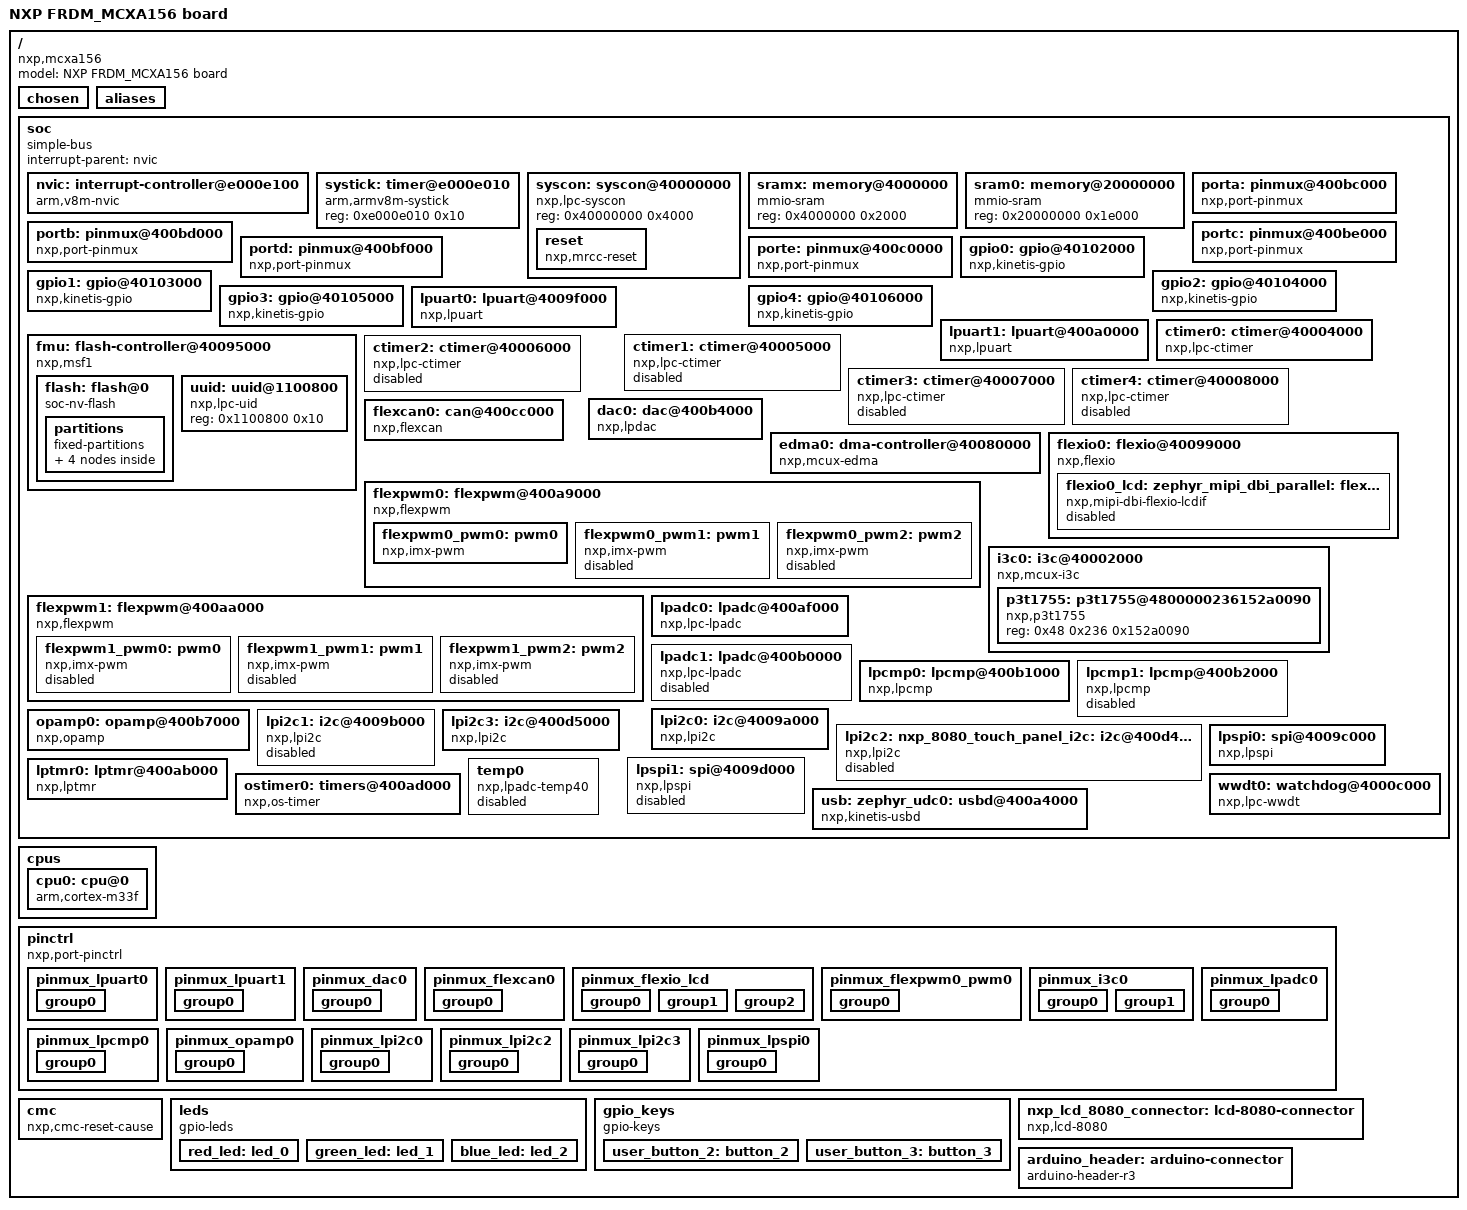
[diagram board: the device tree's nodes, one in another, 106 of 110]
/dts-v1/;

/* node '/' defined in zephyr/dts/common/skeleton.dtsi:9 */
/ {
	#address-cells = < 0x1 >;         /* in zephyr/dts/common/skeleton.dtsi:10 */
	#size-cells = < 0x1 >;            /* in zephyr/dts/common/skeleton.dtsi:11 */
	model = "NXP FRDM_MCXA156 board"; /* in zephyr/boards/nxp/frdm_mcxa156/frdm_mcxa156.dts:16 */
	compatible = "nxp,mcxa156",
	             "nxp,mcx";           /* in zephyr/boards/nxp/frdm_mcxa156/frdm_mcxa156.dts:17 */

	/* node '/chosen' defined in zephyr/dts/common/skeleton.dtsi:13 */
	chosen {
		zephyr,sram = &sram0;                     /* in zephyr/boards/nxp/frdm_mcxa156/frdm_mcxa156.dts:33 */
		zephyr,flash = &flash;                    /* in zephyr/boards/nxp/frdm_mcxa156/frdm_mcxa156.dts:34 */
		zephyr,flash-controller = &fmu;           /* in zephyr/boards/nxp/frdm_mcxa156/frdm_mcxa156.dts:35 */
		zephyr,code-partition = &slot0_partition; /* in zephyr/boards/nxp/frdm_mcxa156/frdm_mcxa156.dts:36 */
		zephyr,console = &lpuart0;                /* in zephyr/boards/nxp/frdm_mcxa156/frdm_mcxa156.dts:37 */
		zephyr,shell-uart = &lpuart0;             /* in zephyr/boards/nxp/frdm_mcxa156/frdm_mcxa156.dts:38 */
		zephyr,uart-mcumgr = &lpuart0;            /* in zephyr/boards/nxp/frdm_mcxa156/frdm_mcxa156.dts:39 */
		zephyr,canbus = &flexcan0;                /* in zephyr/boards/nxp/frdm_mcxa156/frdm_mcxa156.dts:40 */
	};

	/* node '/aliases' defined in zephyr/dts/common/skeleton.dtsi:15 */
	aliases {
		led0 = &red_led;                  /* in zephyr/boards/nxp/frdm_mcxa156/frdm_mcxa156.dts:20 */
		led1 = &green_led;                /* in zephyr/boards/nxp/frdm_mcxa156/frdm_mcxa156.dts:21 */
		led2 = &blue_led;                 /* in zephyr/boards/nxp/frdm_mcxa156/frdm_mcxa156.dts:22 */
		sw0 = &user_button_2;             /* in zephyr/boards/nxp/frdm_mcxa156/frdm_mcxa156.dts:23 */
		sw1 = &user_button_3;             /* in zephyr/boards/nxp/frdm_mcxa156/frdm_mcxa156.dts:24 */
		pwm-0 = &flexpwm0_pwm0;           /* in zephyr/boards/nxp/frdm_mcxa156/frdm_mcxa156.dts:25 */
		mcuboot-button0 = &user_button_2; /* in zephyr/boards/nxp/frdm_mcxa156/frdm_mcxa156.dts:26 */
		watchdog0 = &wwdt0;               /* in zephyr/boards/nxp/frdm_mcxa156/frdm_mcxa156.dts:27 */
		ambient-temp0 = &p3t1755;         /* in zephyr/boards/nxp/frdm_mcxa156/frdm_mcxa156.dts:28 */
		die-temp0 = &temp0;               /* in zephyr/boards/nxp/frdm_mcxa156/frdm_mcxa156.dts:29 */
	};

	/* node '/soc' defined in zephyr/dts/arm/armv8-m.dtsi:6 */
	soc {
		#address-cells = < 0x1 >;     /* in zephyr/dts/arm/armv8-m.dtsi:7 */
		#size-cells = < 0x1 >;        /* in zephyr/dts/arm/armv8-m.dtsi:8 */
		compatible = "simple-bus";    /* in zephyr/dts/arm/armv8-m.dtsi:9 */
		interrupt-parent = < &nvic >; /* in zephyr/dts/arm/armv8-m.dtsi:10 */
		ranges;                       /* in zephyr/dts/arm/armv8-m.dtsi:11 */

		/* node '/soc/interrupt-controller@e000e100' defined in zephyr/dts/arm/armv8-m.dtsi:13 */
		nvic: interrupt-controller@e000e100 {
			#address-cells = < 0x1 >;            /* in zephyr/dts/arm/armv8-m.dtsi:14 */
			compatible = "arm,v8m-nvic";         /* in zephyr/dts/arm/armv8-m.dtsi:15 */
			reg = < 0xe000e100 0xc00 >;          /* in zephyr/dts/arm/armv8-m.dtsi:16 */
			interrupt-controller;                /* in zephyr/dts/arm/armv8-m.dtsi:17 */
			#interrupt-cells = < 0x2 >;          /* in zephyr/dts/arm/armv8-m.dtsi:18 */
			arm,num-irq-priority-bits = < 0x3 >; /* in zephyr/dts/arm/nxp/nxp_mcxa156.dtsi:547 */
			phandle = < 0x1 >;                   /* in zephyr/dts/arm/armv8-m.dtsi:10 */
		};

		/* node '/soc/timer@e000e010' defined in zephyr/dts/arm/armv8-m.dtsi:21 */
		systick: timer@e000e010 {
			compatible = "arm,armv8m-systick"; /* in zephyr/dts/arm/armv8-m.dtsi:22 */
			reg = < 0xe000e010 0x10 >;         /* in zephyr/dts/arm/armv8-m.dtsi:23 */
		};

		/* node '/soc/syscon@40000000' defined in zephyr/dts/arm/nxp/nxp_mcxa156.dtsi:38 */
		syscon: syscon@40000000 {
			compatible = "nxp,lpc-syscon"; /* in zephyr/dts/arm/nxp/nxp_mcxa156.dtsi:39 */
			reg = < 0x40000000 0x4000 >;   /* in zephyr/dts/arm/nxp/nxp_mcxa156.dtsi:40 */
			#clock-cells = < 0x1 >;        /* in zephyr/dts/arm/nxp/nxp_mcxa156.dtsi:41 */
			phandle = < 0x2 >;             /* in zephyr/dts/arm/nxp/nxp_mcxa156.dtsi:62 */

			/* node '/soc/syscon@40000000/reset' defined in zephyr/dts/arm/nxp/nxp_mcxa156.dtsi:43 */
			reset: reset {
				compatible = "nxp,mrcc-reset"; /* in zephyr/dts/arm/nxp/nxp_mcxa156.dtsi:44 */
				#reset-cells = < 0x1 >;        /* in zephyr/dts/arm/nxp/nxp_mcxa156.dtsi:45 */
			};
		};

		/* node '/soc/memory@4000000' defined in zephyr/dts/arm/nxp/nxp_mcxa156.dtsi:49 */
		sramx: memory@4000000 {
			compatible = "mmio-sram";   /* in zephyr/dts/arm/nxp/nxp_mcxa156.dtsi:50 */
			reg = < 0x4000000 0x2000 >; /* in zephyr/dts/arm/nxp/nxp_mcxa156.dtsi:51 */
		};

		/* node '/soc/memory@20000000' defined in zephyr/dts/arm/nxp/nxp_mcxa156.dtsi:54 */
		sram0: memory@20000000 {
			compatible = "mmio-sram";     /* in zephyr/dts/arm/nxp/nxp_mcxa156.dtsi:55 */
			reg = < 0x20000000 0x1e000 >; /* in zephyr/dts/arm/nxp/nxp_mcxa156.dtsi:56 */
		};

		/* node '/soc/pinmux@400bc000' defined in zephyr/dts/arm/nxp/nxp_mcxa156.dtsi:59 */
		porta: pinmux@400bc000 {
			compatible = "nxp,port-pinmux"; /* in zephyr/dts/arm/nxp/nxp_mcxa156.dtsi:60 */
			reg = < 0x400bc000 0x1000 >;    /* in zephyr/dts/arm/nxp/nxp_mcxa156.dtsi:61 */
			clocks = < &syscon 0xc00 >;     /* in zephyr/dts/arm/nxp/nxp_mcxa156.dtsi:62 */
			phandle = < 0x3 >;              /* in zephyr/dts/arm/nxp/nxp_mcxa156.dtsi:95 */
		};

		/* node '/soc/pinmux@400bd000' defined in zephyr/dts/arm/nxp/nxp_mcxa156.dtsi:65 */
		portb: pinmux@400bd000 {
			compatible = "nxp,port-pinmux"; /* in zephyr/dts/arm/nxp/nxp_mcxa156.dtsi:66 */
			reg = < 0x400bd000 0x1000 >;    /* in zephyr/dts/arm/nxp/nxp_mcxa156.dtsi:67 */
			clocks = < &syscon 0xc01 >;     /* in zephyr/dts/arm/nxp/nxp_mcxa156.dtsi:68 */
			phandle = < 0x4 >;              /* in zephyr/dts/arm/nxp/nxp_mcxa156.dtsi:105 */
		};

		/* node '/soc/pinmux@400be000' defined in zephyr/dts/arm/nxp/nxp_mcxa156.dtsi:71 */
		portc: pinmux@400be000 {
			compatible = "nxp,port-pinmux"; /* in zephyr/dts/arm/nxp/nxp_mcxa156.dtsi:72 */
			reg = < 0x400be000 0x1000 >;    /* in zephyr/dts/arm/nxp/nxp_mcxa156.dtsi:73 */
			clocks = < &syscon 0xc02 >;     /* in zephyr/dts/arm/nxp/nxp_mcxa156.dtsi:74 */
			phandle = < 0x5 >;              /* in zephyr/dts/arm/nxp/nxp_mcxa156.dtsi:115 */
		};

		/* node '/soc/pinmux@400bf000' defined in zephyr/dts/arm/nxp/nxp_mcxa156.dtsi:77 */
		portd: pinmux@400bf000 {
			compatible = "nxp,port-pinmux"; /* in zephyr/dts/arm/nxp/nxp_mcxa156.dtsi:78 */
			reg = < 0x400bf000 0x1000 >;    /* in zephyr/dts/arm/nxp/nxp_mcxa156.dtsi:79 */
			clocks = < &syscon 0xc03 >;     /* in zephyr/dts/arm/nxp/nxp_mcxa156.dtsi:80 */
			phandle = < 0x6 >;              /* in zephyr/dts/arm/nxp/nxp_mcxa156.dtsi:125 */
		};

		/* node '/soc/pinmux@400c0000' defined in zephyr/dts/arm/nxp/nxp_mcxa156.dtsi:83 */
		porte: pinmux@400c0000 {
			compatible = "nxp,port-pinmux"; /* in zephyr/dts/arm/nxp/nxp_mcxa156.dtsi:84 */
			reg = < 0x400c0000 0x1000 >;    /* in zephyr/dts/arm/nxp/nxp_mcxa156.dtsi:85 */
			clocks = < &syscon 0xc04 >;     /* in zephyr/dts/arm/nxp/nxp_mcxa156.dtsi:86 */
			phandle = < 0x7 >;              /* in zephyr/dts/arm/nxp/nxp_mcxa156.dtsi:135 */
		};

		/* node '/soc/gpio@40102000' defined in zephyr/dts/arm/nxp/nxp_mcxa156.dtsi:89 */
		gpio0: gpio@40102000 {
			compatible = "nxp,kinetis-gpio"; /* in zephyr/dts/arm/nxp/nxp_mcxa156.dtsi:90 */
			reg = < 0x40102000 0x1000 >;     /* in zephyr/dts/arm/nxp/nxp_mcxa156.dtsi:91 */
			interrupts = < 0x47 0x0 >;       /* in zephyr/dts/arm/nxp/nxp_mcxa156.dtsi:92 */
			gpio-controller;                 /* in zephyr/dts/arm/nxp/nxp_mcxa156.dtsi:93 */
			#gpio-cells = < 0x2 >;           /* in zephyr/dts/arm/nxp/nxp_mcxa156.dtsi:94 */
			nxp,kinetis-port = < &porta >;   /* in zephyr/dts/arm/nxp/nxp_mcxa156.dtsi:95 */
			status = "okay";                 /* in zephyr/boards/nxp/frdm_mcxa156/frdm_mcxa156.dts:126 */
			phandle = < 0x1a >;              /* in zephyr/boards/nxp/frdm_mcxa156/frdm_mcxa156.dts:73 */
		};

		/* node '/soc/gpio@40103000' defined in zephyr/dts/arm/nxp/nxp_mcxa156.dtsi:98 */
		gpio1: gpio@40103000 {
			compatible = "nxp,kinetis-gpio"; /* in zephyr/dts/arm/nxp/nxp_mcxa156.dtsi:99 */
			reg = < 0x40103000 0x1000 >;     /* in zephyr/dts/arm/nxp/nxp_mcxa156.dtsi:101 */
			interrupts = < 0x48 0x0 >;       /* in zephyr/dts/arm/nxp/nxp_mcxa156.dtsi:102 */
			gpio-controller;                 /* in zephyr/dts/arm/nxp/nxp_mcxa156.dtsi:103 */
			#gpio-cells = < 0x2 >;           /* in zephyr/dts/arm/nxp/nxp_mcxa156.dtsi:104 */
			nxp,kinetis-port = < &portb >;   /* in zephyr/dts/arm/nxp/nxp_mcxa156.dtsi:105 */
			status = "okay";                 /* in zephyr/boards/nxp/frdm_mcxa156/frdm_mcxa156.dts:130 */
			phandle = < 0x19 >;              /* in zephyr/boards/nxp/frdm_mcxa156/frdm_mcxa156.dts:67 */
		};

		/* node '/soc/gpio@40104000' defined in zephyr/dts/arm/nxp/nxp_mcxa156.dtsi:108 */
		gpio2: gpio@40104000 {
			compatible = "nxp,kinetis-gpio"; /* in zephyr/dts/arm/nxp/nxp_mcxa156.dtsi:109 */
			reg = < 0x40104000 0x1000 >;     /* in zephyr/dts/arm/nxp/nxp_mcxa156.dtsi:111 */
			interrupts = < 0x49 0x0 >;       /* in zephyr/dts/arm/nxp/nxp_mcxa156.dtsi:112 */
			gpio-controller;                 /* in zephyr/dts/arm/nxp/nxp_mcxa156.dtsi:113 */
			#gpio-cells = < 0x2 >;           /* in zephyr/dts/arm/nxp/nxp_mcxa156.dtsi:114 */
			nxp,kinetis-port = < &portc >;   /* in zephyr/dts/arm/nxp/nxp_mcxa156.dtsi:115 */
			status = "okay";                 /* in zephyr/boards/nxp/frdm_mcxa156/frdm_mcxa156.dts:134 */
			phandle = < 0xe >;               /* in zephyr/boards/nxp/frdm_mcxa156/frdm_mcxa156.dts:198 */
		};

		/* node '/soc/gpio@40105000' defined in zephyr/dts/arm/nxp/nxp_mcxa156.dtsi:118 */
		gpio3: gpio@40105000 {
			compatible = "nxp,kinetis-gpio"; /* in zephyr/dts/arm/nxp/nxp_mcxa156.dtsi:119 */
			reg = < 0x40105000 0x1000 >;     /* in zephyr/dts/arm/nxp/nxp_mcxa156.dtsi:121 */
			interrupts = < 0x4a 0x0 >;       /* in zephyr/dts/arm/nxp/nxp_mcxa156.dtsi:122 */
			gpio-controller;                 /* in zephyr/dts/arm/nxp/nxp_mcxa156.dtsi:123 */
			#gpio-cells = < 0x2 >;           /* in zephyr/dts/arm/nxp/nxp_mcxa156.dtsi:124 */
			nxp,kinetis-port = < &portd >;   /* in zephyr/dts/arm/nxp/nxp_mcxa156.dtsi:125 */
			status = "okay";                 /* in zephyr/boards/nxp/frdm_mcxa156/frdm_mcxa156.dts:138 */
			phandle = < 0xd >;               /* in zephyr/boards/nxp/frdm_mcxa156/frdm_mcxa156.dts:197 */
		};

		/* node '/soc/gpio@40106000' defined in zephyr/dts/arm/nxp/nxp_mcxa156.dtsi:128 */
		gpio4: gpio@40106000 {
			compatible = "nxp,kinetis-gpio"; /* in zephyr/dts/arm/nxp/nxp_mcxa156.dtsi:129 */
			reg = < 0x40106000 0x1000 >;     /* in zephyr/dts/arm/nxp/nxp_mcxa156.dtsi:131 */
			interrupts = < 0x4b 0x0 >;       /* in zephyr/dts/arm/nxp/nxp_mcxa156.dtsi:132 */
			gpio-controller;                 /* in zephyr/dts/arm/nxp/nxp_mcxa156.dtsi:133 */
			#gpio-cells = < 0x2 >;           /* in zephyr/dts/arm/nxp/nxp_mcxa156.dtsi:134 */
			nxp,kinetis-port = < &porte >;   /* in zephyr/dts/arm/nxp/nxp_mcxa156.dtsi:135 */
			status = "okay";                 /* in zephyr/boards/nxp/frdm_mcxa156/frdm_mcxa156.dts:142 */
		};

		/* node '/soc/lpuart@4009f000' defined in zephyr/dts/arm/nxp/nxp_mcxa156.dtsi:138 */
		lpuart0: lpuart@4009f000 {
			compatible = "nxp,lpuart";       /* in zephyr/dts/arm/nxp/nxp_mcxa156.dtsi:139 */
			reg = < 0x4009f000 0x1000 >;     /* in zephyr/dts/arm/nxp/nxp_mcxa156.dtsi:140 */
			interrupts = < 0x1f 0x0 >;       /* in zephyr/dts/arm/nxp/nxp_mcxa156.dtsi:141 */
			clocks = < &syscon 0x1300 >;     /* in zephyr/dts/arm/nxp/nxp_mcxa156.dtsi:142 */
			dmas = < &edma0 0x0 0x15 >,
			       < &edma0 0x1 0x16 >;      /* in zephyr/dts/arm/nxp/nxp_mcxa156.dtsi:144 */
			dma-names = "rx",
			            "tx";                /* in zephyr/dts/arm/nxp/nxp_mcxa156.dtsi:145 */
			status = "okay";                 /* in zephyr/boards/nxp/frdm_mcxa156/frdm_mcxa156.dts:146 */
			current-speed = < 0x1c200 >;     /* in zephyr/boards/nxp/frdm_mcxa156/frdm_mcxa156.dts:147 */
			pinctrl-0 = < &pinmux_lpuart0 >; /* in zephyr/boards/nxp/frdm_mcxa156/frdm_mcxa156.dts:148 */
			pinctrl-names = "default";       /* in zephyr/boards/nxp/frdm_mcxa156/frdm_mcxa156.dts:149 */
		};

		/* node '/soc/lpuart@400a0000' defined in zephyr/dts/arm/nxp/nxp_mcxa156.dtsi:148 */
		lpuart1: lpuart@400a0000 {
			compatible = "nxp,lpuart";       /* in zephyr/dts/arm/nxp/nxp_mcxa156.dtsi:149 */
			reg = < 0x400a0000 0x1000 >;     /* in zephyr/dts/arm/nxp/nxp_mcxa156.dtsi:150 */
			interrupts = < 0x20 0x0 >;       /* in zephyr/dts/arm/nxp/nxp_mcxa156.dtsi:151 */
			clocks = < &syscon 0x1301 >;     /* in zephyr/dts/arm/nxp/nxp_mcxa156.dtsi:152 */
			dmas = < &edma0 0x2 0x17 >,
			       < &edma0 0x3 0x18 >;      /* in zephyr/dts/arm/nxp/nxp_mcxa156.dtsi:154 */
			dma-names = "rx",
			            "tx";                /* in zephyr/dts/arm/nxp/nxp_mcxa156.dtsi:155 */
			status = "okay";                 /* in zephyr/boards/nxp/frdm_mcxa156/frdm_mcxa156.dts:153 */
			current-speed = < 0x1c200 >;     /* in zephyr/boards/nxp/frdm_mcxa156/frdm_mcxa156.dts:154 */
			pinctrl-0 = < &pinmux_lpuart1 >; /* in zephyr/boards/nxp/frdm_mcxa156/frdm_mcxa156.dts:155 */
			pinctrl-names = "default";       /* in zephyr/boards/nxp/frdm_mcxa156/frdm_mcxa156.dts:156 */
		};

		/* node '/soc/flash-controller@40095000' defined in zephyr/dts/arm/nxp/nxp_mcxa156.dtsi:158 */
		fmu: flash-controller@40095000 {
			compatible = "nxp,msf1";     /* in zephyr/dts/arm/nxp/nxp_mcxa156.dtsi:159 */
			reg = < 0x40095000 0x1000 >; /* in zephyr/dts/arm/nxp/nxp_mcxa156.dtsi:160 */
			interrupts = < 0xc 0x0 >;    /* in zephyr/dts/arm/nxp/nxp_mcxa156.dtsi:161 */
			#address-cells = < 0x1 >;    /* in zephyr/dts/arm/nxp/nxp_mcxa156.dtsi:163 */
			#size-cells = < 0x1 >;       /* in zephyr/dts/arm/nxp/nxp_mcxa156.dtsi:164 */

			/* node '/soc/flash-controller@40095000/flash@0' defined in zephyr/dts/arm/nxp/nxp_mcxa156.dtsi:166 */
			flash: flash@0 {
				compatible = "soc-nv-flash";   /* in zephyr/dts/arm/nxp/nxp_mcxa156.dtsi:167 */
				reg = < 0x0 0x100000 >;        /* in zephyr/dts/arm/nxp/nxp_mcxa156.dtsi:168 */
				erase-block-size = < 0x2000 >; /* in zephyr/dts/arm/nxp/nxp_mcxa156.dtsi:169 */
				write-block-size = < 0x10 >;   /* in zephyr/dts/arm/nxp/nxp_mcxa156.dtsi:170 */

				/* node '/soc/flash-controller@40095000/flash@0/partitions' defined in zephyr/boards/nxp/frdm_mcxa156/frdm_mcxa156.dts:283 */
				partitions {
					compatible = "fixed-partitions"; /* in zephyr/boards/nxp/frdm_mcxa156/frdm_mcxa156.dts:284 */
					#address-cells = < 0x1 >;        /* in zephyr/boards/nxp/frdm_mcxa156/frdm_mcxa156.dts:285 */
					#size-cells = < 0x1 >;           /* in zephyr/boards/nxp/frdm_mcxa156/frdm_mcxa156.dts:286 */

					/* node '/soc/flash-controller@40095000/flash@0/partitions/partition@0' defined in zephyr/boards/nxp/frdm_mcxa156/frdm_mcxa156.dts:288 */
					boot_partition: partition@0 {
						label = "mcuboot";     /* in zephyr/boards/nxp/frdm_mcxa156/frdm_mcxa156.dts:289 */
						reg = < 0x0 0x10000 >; /* in zephyr/boards/nxp/frdm_mcxa156/frdm_mcxa156.dts:290 */
						read-only;             /* in zephyr/boards/nxp/frdm_mcxa156/frdm_mcxa156.dts:291 */
					};

					/* node '/soc/flash-controller@40095000/flash@0/partitions/partition@10000' defined in zephyr/boards/nxp/frdm_mcxa156/frdm_mcxa156.dts:294 */
					slot0_partition: partition@10000 {
						label = "image-0";         /* in zephyr/boards/nxp/frdm_mcxa156/frdm_mcxa156.dts:295 */
						reg = < 0x10000 0x6a000 >; /* in zephyr/boards/nxp/frdm_mcxa156/frdm_mcxa156.dts:296 */
					};

					/* node '/soc/flash-controller@40095000/flash@0/partitions/partition@7a000' defined in zephyr/boards/nxp/frdm_mcxa156/frdm_mcxa156.dts:299 */
					slot1_partition: partition@7a000 {
						label = "image-1";         /* in zephyr/boards/nxp/frdm_mcxa156/frdm_mcxa156.dts:300 */
						reg = < 0x7a000 0x6a000 >; /* in zephyr/boards/nxp/frdm_mcxa156/frdm_mcxa156.dts:301 */
					};

					/* node '/soc/flash-controller@40095000/flash@0/partitions/partition@e4000' defined in zephyr/boards/nxp/frdm_mcxa156/frdm_mcxa156.dts:304 */
					storage_partition: partition@e4000 {
						label = "storage";         /* in zephyr/boards/nxp/frdm_mcxa156/frdm_mcxa156.dts:305 */
						reg = < 0xe4000 0x1c000 >; /* in zephyr/boards/nxp/frdm_mcxa156/frdm_mcxa156.dts:306 */
					};
				};
			};

			/* node '/soc/flash-controller@40095000/uuid@1100800' defined in zephyr/dts/arm/nxp/nxp_mcxa156.dtsi:173 */
			uuid: uuid@1100800 {
				compatible = "nxp,lpc-uid"; /* in zephyr/dts/arm/nxp/nxp_mcxa156.dtsi:174 */
				reg = < 0x1100800 0x10 >;   /* in zephyr/dts/arm/nxp/nxp_mcxa156.dtsi:175 */
			};
		};

		/* node '/soc/ctimer@40004000' defined in zephyr/dts/arm/nxp/nxp_mcxa156.dtsi:179 */
		ctimer0: ctimer@40004000 {
			compatible = "nxp,lpc-ctimer"; /* in zephyr/dts/arm/nxp/nxp_mcxa156.dtsi:180 */
			reg = < 0x40004000 0x1000 >;   /* in zephyr/dts/arm/nxp/nxp_mcxa156.dtsi:181 */
			interrupts = < 0x27 0x0 >;     /* in zephyr/dts/arm/nxp/nxp_mcxa156.dtsi:182 */
			clk-source = < 0x1 >;          /* in zephyr/dts/arm/nxp/nxp_mcxa156.dtsi:184 */
			clocks = < &syscon 0x0 >;      /* in zephyr/dts/arm/nxp/nxp_mcxa156.dtsi:185 */
			mode = < 0x0 >;                /* in zephyr/dts/arm/nxp/nxp_mcxa156.dtsi:186 */
			input = < 0x0 >;               /* in zephyr/dts/arm/nxp/nxp_mcxa156.dtsi:187 */
			prescale = < 0x0 >;            /* in zephyr/dts/arm/nxp/nxp_mcxa156.dtsi:188 */
			status = "okay";               /* in zephyr/boards/nxp/frdm_mcxa156/frdm_mcxa156.dts:160 */
		};

		/* node '/soc/ctimer@40005000' defined in zephyr/dts/arm/nxp/nxp_mcxa156.dtsi:191 */
		ctimer1: ctimer@40005000 {
			compatible = "nxp,lpc-ctimer"; /* in zephyr/dts/arm/nxp/nxp_mcxa156.dtsi:192 */
			reg = < 0x40005000 0x1000 >;   /* in zephyr/dts/arm/nxp/nxp_mcxa156.dtsi:193 */
			interrupts = < 0x28 0x0 >;     /* in zephyr/dts/arm/nxp/nxp_mcxa156.dtsi:194 */
			status = "disabled";           /* in zephyr/dts/arm/nxp/nxp_mcxa156.dtsi:195 */
			clk-source = < 0x1 >;          /* in zephyr/dts/arm/nxp/nxp_mcxa156.dtsi:196 */
			clocks = < &syscon 0x1 >;      /* in zephyr/dts/arm/nxp/nxp_mcxa156.dtsi:197 */
			mode = < 0x0 >;                /* in zephyr/dts/arm/nxp/nxp_mcxa156.dtsi:198 */
			input = < 0x0 >;               /* in zephyr/dts/arm/nxp/nxp_mcxa156.dtsi:199 */
			prescale = < 0x0 >;            /* in zephyr/dts/arm/nxp/nxp_mcxa156.dtsi:200 */
		};

		/* node '/soc/ctimer@40006000' defined in zephyr/dts/arm/nxp/nxp_mcxa156.dtsi:203 */
		ctimer2: ctimer@40006000 {
			compatible = "nxp,lpc-ctimer"; /* in zephyr/dts/arm/nxp/nxp_mcxa156.dtsi:204 */
			reg = < 0x40006000 0x1000 >;   /* in zephyr/dts/arm/nxp/nxp_mcxa156.dtsi:205 */
			interrupts = < 0x29 0x0 >;     /* in zephyr/dts/arm/nxp/nxp_mcxa156.dtsi:206 */
			status = "disabled";           /* in zephyr/dts/arm/nxp/nxp_mcxa156.dtsi:207 */
			clk-source = < 0x1 >;          /* in zephyr/dts/arm/nxp/nxp_mcxa156.dtsi:208 */
			clocks = < &syscon 0x2 >;      /* in zephyr/dts/arm/nxp/nxp_mcxa156.dtsi:209 */
			mode = < 0x0 >;                /* in zephyr/dts/arm/nxp/nxp_mcxa156.dtsi:210 */
			input = < 0x0 >;               /* in zephyr/dts/arm/nxp/nxp_mcxa156.dtsi:211 */
			prescale = < 0x0 >;            /* in zephyr/dts/arm/nxp/nxp_mcxa156.dtsi:212 */
		};

		/* node '/soc/ctimer@40007000' defined in zephyr/dts/arm/nxp/nxp_mcxa156.dtsi:215 */
		ctimer3: ctimer@40007000 {
			compatible = "nxp,lpc-ctimer"; /* in zephyr/dts/arm/nxp/nxp_mcxa156.dtsi:216 */
			reg = < 0x40007000 0x1000 >;   /* in zephyr/dts/arm/nxp/nxp_mcxa156.dtsi:217 */
			interrupts = < 0x2a 0x0 >;     /* in zephyr/dts/arm/nxp/nxp_mcxa156.dtsi:218 */
			status = "disabled";           /* in zephyr/dts/arm/nxp/nxp_mcxa156.dtsi:219 */
			clk-source = < 0x1 >;          /* in zephyr/dts/arm/nxp/nxp_mcxa156.dtsi:220 */
			clocks = < &syscon 0x3 >;      /* in zephyr/dts/arm/nxp/nxp_mcxa156.dtsi:221 */
			mode = < 0x0 >;                /* in zephyr/dts/arm/nxp/nxp_mcxa156.dtsi:222 */
			input = < 0x0 >;               /* in zephyr/dts/arm/nxp/nxp_mcxa156.dtsi:223 */
			prescale = < 0x0 >;            /* in zephyr/dts/arm/nxp/nxp_mcxa156.dtsi:224 */
		};

		/* node '/soc/ctimer@40008000' defined in zephyr/dts/arm/nxp/nxp_mcxa156.dtsi:227 */
		ctimer4: ctimer@40008000 {
			compatible = "nxp,lpc-ctimer"; /* in zephyr/dts/arm/nxp/nxp_mcxa156.dtsi:228 */
			reg = < 0x40008000 0x1000 >;   /* in zephyr/dts/arm/nxp/nxp_mcxa156.dtsi:229 */
			interrupts = < 0x2b 0x0 >;     /* in zephyr/dts/arm/nxp/nxp_mcxa156.dtsi:230 */
			status = "disabled";           /* in zephyr/dts/arm/nxp/nxp_mcxa156.dtsi:231 */
			clk-source = < 0x1 >;          /* in zephyr/dts/arm/nxp/nxp_mcxa156.dtsi:232 */
			clocks = < &syscon 0x4 >;      /* in zephyr/dts/arm/nxp/nxp_mcxa156.dtsi:233 */
			mode = < 0x0 >;                /* in zephyr/dts/arm/nxp/nxp_mcxa156.dtsi:234 */
			input = < 0x0 >;               /* in zephyr/dts/arm/nxp/nxp_mcxa156.dtsi:235 */
			prescale = < 0x0 >;            /* in zephyr/dts/arm/nxp/nxp_mcxa156.dtsi:236 */
		};

		/* node '/soc/dac@400b4000' defined in zephyr/dts/arm/nxp/nxp_mcxa156.dtsi:239 */
		dac0: dac@400b4000 {
			compatible = "nxp,lpdac";     /* in zephyr/dts/arm/nxp/nxp_mcxa156.dtsi:240 */
			reg = < 0x400b4000 0x1000 >;  /* in zephyr/dts/arm/nxp/nxp_mcxa156.dtsi:241 */
			interrupts = < 0x43 0x0 >;    /* in zephyr/dts/arm/nxp/nxp_mcxa156.dtsi:242 */
			voltage-reference = < 0x0 >;  /* in zephyr/dts/arm/nxp/nxp_mcxa156.dtsi:244 */
			#io-channel-cells = < 0x1 >;  /* in zephyr/dts/arm/nxp/nxp_mcxa156.dtsi:245 */
			status = "okay";              /* in zephyr/boards/nxp/frdm_mcxa156/frdm_mcxa156.dts:164 */
			pinctrl-0 = < &pinmux_dac0 >; /* in zephyr/boards/nxp/frdm_mcxa156/frdm_mcxa156.dts:165 */
			pinctrl-names = "default";    /* in zephyr/boards/nxp/frdm_mcxa156/frdm_mcxa156.dts:166 */
		};

		/* node '/soc/dma-controller@40080000' defined in zephyr/dts/arm/nxp/nxp_mcxa156.dtsi:248 */
		edma0: dma-controller@40080000 {
			#dma-cells = < 0x2 >;         /* in zephyr/dts/arm/nxp/nxp_mcxa156.dtsi:249 */
			compatible = "nxp,mcux-edma"; /* in zephyr/dts/arm/nxp/nxp_mcxa156.dtsi:250 */
			nxp,version = < 0x4 >;        /* in zephyr/dts/arm/nxp/nxp_mcxa156.dtsi:251 */
			dma-channels = < 0x8 >;       /* in zephyr/dts/arm/nxp/nxp_mcxa156.dtsi:252 */
			dma-requests = < 0x56 >;      /* in zephyr/dts/arm/nxp/nxp_mcxa156.dtsi:253 */
			reg = < 0x40080000 0x1000 >;  /* in zephyr/dts/arm/nxp/nxp_mcxa156.dtsi:255 */
			interrupts = < 0x2 0x0 >,
			             < 0x3 0x0 >,
			             < 0x4 0x0 >,
			             < 0x5 0x0 >,
			             < 0x6 0x0 >,
			             < 0x7 0x0 >,
			             < 0x8 0x0 >,
			             < 0x9 0x0 >;     /* in zephyr/dts/arm/nxp/nxp_mcxa156.dtsi:256 */
			no-error-irq;                 /* in zephyr/dts/arm/nxp/nxp_mcxa156.dtsi:258 */
			status = "okay";              /* in zephyr/boards/nxp/frdm_mcxa156/frdm_mcxa156.dts:170 */
			phandle = < 0x8 >;            /* in zephyr/dts/arm/nxp/nxp_mcxa156.dtsi:144 */
		};

		/* node '/soc/can@400cc000' defined in zephyr/dts/arm/nxp/nxp_mcxa156.dtsi:262 */
		flexcan0: can@400cc000 {
			compatible = "nxp,flexcan";       /* in zephyr/dts/arm/nxp/nxp_mcxa156.dtsi:263 */
			reg = < 0x400cc000 0x1000 >;      /* in zephyr/dts/arm/nxp/nxp_mcxa156.dtsi:264 */
			interrupts = < 0x13 0x0 >;        /* in zephyr/dts/arm/nxp/nxp_mcxa156.dtsi:265 */
			interrupt-names = "common";       /* in zephyr/dts/arm/nxp/nxp_mcxa156.dtsi:266 */
			clocks = < &syscon 0x1000 >;      /* in zephyr/dts/arm/nxp/nxp_mcxa156.dtsi:267 */
			clk-source = < 0x0 >;             /* in zephyr/dts/arm/nxp/nxp_mcxa156.dtsi:268 */
			status = "okay";                  /* in zephyr/boards/nxp/frdm_mcxa156/frdm_mcxa156.dts:174 */
			pinctrl-0 = < &pinmux_flexcan0 >; /* in zephyr/boards/nxp/frdm_mcxa156/frdm_mcxa156.dts:175 */
			pinctrl-names = "default";        /* in zephyr/boards/nxp/frdm_mcxa156/frdm_mcxa156.dts:176 */
		};

		/* node '/soc/flexio@40099000' defined in zephyr/dts/arm/nxp/nxp_mcxa156.dtsi:272 */
		flexio0: flexio@40099000 {
			compatible = "nxp,flexio";   /* in zephyr/dts/arm/nxp/nxp_mcxa156.dtsi:273 */
			reg = < 0x40099000 0x1000 >; /* in zephyr/dts/arm/nxp/nxp_mcxa156.dtsi:274 */
			interrupts = < 0x17 0x0 >;   /* in zephyr/dts/arm/nxp/nxp_mcxa156.dtsi:276 */
			clocks = < &syscon 0x1100 >; /* in zephyr/dts/arm/nxp/nxp_mcxa156.dtsi:277 */
			status = "okay";             /* in zephyr/boards/nxp/frdm_mcxa156/frdm_mcxa156.dts:180 */

			/* node '/soc/flexio@40099000/flexio0-lcd' defined in zephyr/dts/arm/nxp/nxp_mcxa156.dtsi:279 */
			flexio0_lcd: zephyr_mipi_dbi_parallel: flexio0-lcd {
				compatible = "nxp,mipi-dbi-flexio-lcdif"; /* in zephyr/dts/arm/nxp/nxp_mcxa156.dtsi:280 */
				status = "disabled";                      /* in zephyr/dts/arm/nxp/nxp_mcxa156.dtsi:281 */
				dmas = < &edma0 0x0 0x47 >;               /* in zephyr/boards/nxp/frdm_mcxa156/frdm_mcxa156.dts:190 */
				dma-names = "tx";                         /* in zephyr/boards/nxp/frdm_mcxa156/frdm_mcxa156.dts:191 */
				shifters-count = < 0x4 >;                 /* in zephyr/boards/nxp/frdm_mcxa156/frdm_mcxa156.dts:192 */
				timers-count = < 0x1 >;                   /* in zephyr/boards/nxp/frdm_mcxa156/frdm_mcxa156.dts:193 */
				enwr-pin = < 0x1f >;                      /* in zephyr/boards/nxp/frdm_mcxa156/frdm_mcxa156.dts:194 */
				rd-pin = < 0x1c >;                        /* in zephyr/boards/nxp/frdm_mcxa156/frdm_mcxa156.dts:195 */
				data-pin-start = < 0x0 >;                 /* in zephyr/boards/nxp/frdm_mcxa156/frdm_mcxa156.dts:196 */
				reset-gpios = < &gpio3 0x0 0x0 >;         /* in zephyr/boards/nxp/frdm_mcxa156/frdm_mcxa156.dts:197 */
				cs-gpios = < &gpio2 0x13 0x0 >;           /* in zephyr/boards/nxp/frdm_mcxa156/frdm_mcxa156.dts:198 */
				rs-gpios = < &gpio2 0x11 0x0 >;           /* in zephyr/boards/nxp/frdm_mcxa156/frdm_mcxa156.dts:199 */
				pinctrl-0 = < &pinmux_flexio_lcd >;       /* in zephyr/boards/nxp/frdm_mcxa156/frdm_mcxa156.dts:200 */
				pinctrl-names = "default";                /* in zephyr/boards/nxp/frdm_mcxa156/frdm_mcxa156.dts:201 */
			};
		};

		/* node '/soc/flexpwm@400a9000' defined in zephyr/dts/arm/nxp/nxp_mcxa156.dtsi:285 */
		flexpwm0: flexpwm@400a9000 {
			compatible = "nxp,flexpwm";       /* in zephyr/dts/arm/nxp/nxp_mcxa156.dtsi:286 */
			reg = < 0x400a9000 0x1000 >;      /* in zephyr/dts/arm/nxp/nxp_mcxa156.dtsi:287 */
			interrupt-names = "RELOAD-ERROR",
			                  "FAULT";        /* in zephyr/dts/arm/nxp/nxp_mcxa156.dtsi:288 */
			interrupts = < 0x2c 0x0 >,
			             < 0x2d 0x0 >;        /* in zephyr/dts/arm/nxp/nxp_mcxa156.dtsi:289 */

			/* node '/soc/flexpwm@400a9000/pwm0' defined in zephyr/dts/arm/nxp/nxp_mcxa156.dtsi:291 */
			flexpwm0_pwm0: pwm0 {
				compatible = "nxp,imx-pwm";            /* in zephyr/dts/arm/nxp/nxp_mcxa156.dtsi:292 */
				index = < 0x0 >;                       /* in zephyr/dts/arm/nxp/nxp_mcxa156.dtsi:293 */
				interrupts = < 0x2e 0x0 >;             /* in zephyr/dts/arm/nxp/nxp_mcxa156.dtsi:294 */
				#pwm-cells = < 0x3 >;                  /* in zephyr/dts/arm/nxp/nxp_mcxa156.dtsi:295 */
				clocks = < &syscon 0x400 >;            /* in zephyr/dts/arm/nxp/nxp_mcxa156.dtsi:296 */
				nxp,prescaler = < 0x80 >;              /* in zephyr/dts/arm/nxp/nxp_mcxa156.dtsi:297 */
				run-in-wait;                           /* in zephyr/dts/arm/nxp/nxp_mcxa156.dtsi:299 */
				status = "okay";                       /* in zephyr/boards/nxp/frdm_mcxa156/frdm_mcxa156.dts:205 */
				pinctrl-0 = < &pinmux_flexpwm0_pwm0 >; /* in zephyr/boards/nxp/frdm_mcxa156/frdm_mcxa156.dts:206 */
				pinctrl-names = "default";             /* in zephyr/boards/nxp/frdm_mcxa156/frdm_mcxa156.dts:207 */
			};

			/* node '/soc/flexpwm@400a9000/pwm1' defined in zephyr/dts/arm/nxp/nxp_mcxa156.dtsi:302 */
			flexpwm0_pwm1: pwm1 {
				compatible = "nxp,imx-pwm"; /* in zephyr/dts/arm/nxp/nxp_mcxa156.dtsi:303 */
				index = < 0x1 >;            /* in zephyr/dts/arm/nxp/nxp_mcxa156.dtsi:304 */
				interrupts = < 0x2f 0x0 >;  /* in zephyr/dts/arm/nxp/nxp_mcxa156.dtsi:305 */
				#pwm-cells = < 0x3 >;       /* in zephyr/dts/arm/nxp/nxp_mcxa156.dtsi:306 */
				clocks = < &syscon 0x400 >; /* in zephyr/dts/arm/nxp/nxp_mcxa156.dtsi:307 */
				nxp,prescaler = < 0x80 >;   /* in zephyr/dts/arm/nxp/nxp_mcxa156.dtsi:308 */
				status = "disabled";        /* in zephyr/dts/arm/nxp/nxp_mcxa156.dtsi:309 */
				run-in-wait;                /* in zephyr/dts/arm/nxp/nxp_mcxa156.dtsi:310 */
			};

			/* node '/soc/flexpwm@400a9000/pwm2' defined in zephyr/dts/arm/nxp/nxp_mcxa156.dtsi:313 */
			flexpwm0_pwm2: pwm2 {
				compatible = "nxp,imx-pwm"; /* in zephyr/dts/arm/nxp/nxp_mcxa156.dtsi:314 */
				index = < 0x2 >;            /* in zephyr/dts/arm/nxp/nxp_mcxa156.dtsi:315 */
				interrupts = < 0x30 0x0 >;  /* in zephyr/dts/arm/nxp/nxp_mcxa156.dtsi:316 */
				#pwm-cells = < 0x3 >;       /* in zephyr/dts/arm/nxp/nxp_mcxa156.dtsi:317 */
				clocks = < &syscon 0x400 >; /* in zephyr/dts/arm/nxp/nxp_mcxa156.dtsi:318 */
				nxp,prescaler = < 0x80 >;   /* in zephyr/dts/arm/nxp/nxp_mcxa156.dtsi:319 */
				status = "disabled";        /* in zephyr/dts/arm/nxp/nxp_mcxa156.dtsi:320 */
				run-in-wait;                /* in zephyr/dts/arm/nxp/nxp_mcxa156.dtsi:321 */
			};
		};

		/* node '/soc/flexpwm@400aa000' defined in zephyr/dts/arm/nxp/nxp_mcxa156.dtsi:325 */
		flexpwm1: flexpwm@400aa000 {
			compatible = "nxp,flexpwm";       /* in zephyr/dts/arm/nxp/nxp_mcxa156.dtsi:326 */
			reg = < 0x400aa000 0x1000 >;      /* in zephyr/dts/arm/nxp/nxp_mcxa156.dtsi:327 */
			interrupt-names = "RELOAD-ERROR",
			                  "FAULT";        /* in zephyr/dts/arm/nxp/nxp_mcxa156.dtsi:328 */
			interrupts = < 0x4f 0x0 >,
			             < 0x50 0x0 >;        /* in zephyr/dts/arm/nxp/nxp_mcxa156.dtsi:329 */

			/* node '/soc/flexpwm@400aa000/pwm0' defined in zephyr/dts/arm/nxp/nxp_mcxa156.dtsi:331 */
			flexpwm1_pwm0: pwm0 {
				compatible = "nxp,imx-pwm"; /* in zephyr/dts/arm/nxp/nxp_mcxa156.dtsi:332 */
				index = < 0x0 >;            /* in zephyr/dts/arm/nxp/nxp_mcxa156.dtsi:333 */
				interrupts = < 0x51 0x0 >;  /* in zephyr/dts/arm/nxp/nxp_mcxa156.dtsi:334 */
				#pwm-cells = < 0x3 >;       /* in zephyr/dts/arm/nxp/nxp_mcxa156.dtsi:335 */
				clocks = < &syscon 0x400 >; /* in zephyr/dts/arm/nxp/nxp_mcxa156.dtsi:336 */
				nxp,prescaler = < 0x80 >;   /* in zephyr/dts/arm/nxp/nxp_mcxa156.dtsi:337 */
				status = "disabled";        /* in zephyr/dts/arm/nxp/nxp_mcxa156.dtsi:338 */
				run-in-wait;                /* in zephyr/dts/arm/nxp/nxp_mcxa156.dtsi:339 */
			};

			/* node '/soc/flexpwm@400aa000/pwm1' defined in zephyr/dts/arm/nxp/nxp_mcxa156.dtsi:342 */
			flexpwm1_pwm1: pwm1 {
				compatible = "nxp,imx-pwm"; /* in zephyr/dts/arm/nxp/nxp_mcxa156.dtsi:343 */
				index = < 0x1 >;            /* in zephyr/dts/arm/nxp/nxp_mcxa156.dtsi:344 */
				interrupts = < 0x52 0x0 >;  /* in zephyr/dts/arm/nxp/nxp_mcxa156.dtsi:345 */
				#pwm-cells = < 0x3 >;       /* in zephyr/dts/arm/nxp/nxp_mcxa156.dtsi:346 */
				clocks = < &syscon 0x400 >; /* in zephyr/dts/arm/nxp/nxp_mcxa156.dtsi:347 */
				nxp,prescaler = < 0x80 >;   /* in zephyr/dts/arm/nxp/nxp_mcxa156.dtsi:348 */
				status = "disabled";        /* in zephyr/dts/arm/nxp/nxp_mcxa156.dtsi:349 */
				run-in-wait;                /* in zephyr/dts/arm/nxp/nxp_mcxa156.dtsi:350 */
			};

			/* node '/soc/flexpwm@400aa000/pwm2' defined in zephyr/dts/arm/nxp/nxp_mcxa156.dtsi:353 */
			flexpwm1_pwm2: pwm2 {
				compatible = "nxp,imx-pwm"; /* in zephyr/dts/arm/nxp/nxp_mcxa156.dtsi:354 */
				index = < 0x2 >;            /* in zephyr/dts/arm/nxp/nxp_mcxa156.dtsi:355 */
				interrupts = < 0x53 0x0 >;  /* in zephyr/dts/arm/nxp/nxp_mcxa156.dtsi:356 */
				#pwm-cells = < 0x3 >;       /* in zephyr/dts/arm/nxp/nxp_mcxa156.dtsi:357 */
				clocks = < &syscon 0x400 >; /* in zephyr/dts/arm/nxp/nxp_mcxa156.dtsi:358 */
				nxp,prescaler = < 0x80 >;   /* in zephyr/dts/arm/nxp/nxp_mcxa156.dtsi:359 */
				status = "disabled";        /* in zephyr/dts/arm/nxp/nxp_mcxa156.dtsi:360 */
				run-in-wait;                /* in zephyr/dts/arm/nxp/nxp_mcxa156.dtsi:361 */
			};
		};

		/* node '/soc/i3c@40002000' defined in zephyr/dts/arm/nxp/nxp_mcxa156.dtsi:365 */
		i3c0: i3c@40002000 {
			compatible = "nxp,mcux-i3c";  /* in zephyr/dts/arm/nxp/nxp_mcxa156.dtsi:366 */
			reg = < 0x40002000 0x1000 >;  /* in zephyr/dts/arm/nxp/nxp_mcxa156.dtsi:367 */
			interrupts = < 0x18 0x0 >;    /* in zephyr/dts/arm/nxp/nxp_mcxa156.dtsi:368 */
			clocks = < &syscon 0x600 >;   /* in zephyr/dts/arm/nxp/nxp_mcxa156.dtsi:369 */
			clk-divider = < 0x4 >;        /* in zephyr/dts/arm/nxp/nxp_mcxa156.dtsi:370 */
			clk-divider-slow = < 0x1 >;   /* in zephyr/dts/arm/nxp/nxp_mcxa156.dtsi:371 */
			clk-divider-tc = < 0x1 >;     /* in zephyr/dts/arm/nxp/nxp_mcxa156.dtsi:372 */
			#address-cells = < 0x3 >;     /* in zephyr/dts/arm/nxp/nxp_mcxa156.dtsi:374 */
			#size-cells = < 0x0 >;        /* in zephyr/dts/arm/nxp/nxp_mcxa156.dtsi:375 */
			status = "okay";              /* in zephyr/boards/nxp/frdm_mcxa156/frdm_mcxa156.dts:211 */
			pinctrl-0 = < &pinmux_i3c0 >; /* in zephyr/boards/nxp/frdm_mcxa156/frdm_mcxa156.dts:212 */
			pinctrl-names = "default";    /* in zephyr/boards/nxp/frdm_mcxa156/frdm_mcxa156.dts:213 */
			i2c-scl-hz = < 0x61a80 >;     /* in zephyr/boards/nxp/frdm_mcxa156/frdm_mcxa156.dts:215 */
			i3c-scl-hz = < 0x3d0900 >;    /* in zephyr/boards/nxp/frdm_mcxa156/frdm_mcxa156.dts:216 */
			i3c-od-scl-hz = < 0x16e360 >; /* in zephyr/boards/nxp/frdm_mcxa156/frdm_mcxa156.dts:217 */

			/* node '/soc/i3c@40002000/p3t1755@4800000236152a0090' defined in zephyr/boards/nxp/frdm_mcxa156/frdm_mcxa156.dts:219 */
			p3t1755: p3t1755@4800000236152a0090 {
				compatible = "nxp,p3t1755";      /* in zephyr/boards/nxp/frdm_mcxa156/frdm_mcxa156.dts:220 */
				reg = < 0x48 0x236 0x152a0090 >; /* in zephyr/boards/nxp/frdm_mcxa156/frdm_mcxa156.dts:221 */
				status = "okay";                 /* in zephyr/boards/nxp/frdm_mcxa156/frdm_mcxa156.dts:222 */
			};
		};

		/* node '/soc/lpadc@400af000' defined in zephyr/dts/arm/nxp/nxp_mcxa156.dtsi:378 */
		lpadc0: lpadc@400af000 {
			compatible = "nxp,lpc-lpadc";   /* in zephyr/dts/arm/nxp/nxp_mcxa156.dtsi:379 */
			reg = < 0x400af000 0x1000 >;    /* in zephyr/dts/arm/nxp/nxp_mcxa156.dtsi:380 */
			interrupts = < 0x3e 0x0 >;      /* in zephyr/dts/arm/nxp/nxp_mcxa156.dtsi:381 */
			clk-divider = < 0x1 >;          /* in zephyr/dts/arm/nxp/nxp_mcxa156.dtsi:383 */
			clk-source = < 0x0 >;           /* in zephyr/dts/arm/nxp/nxp_mcxa156.dtsi:384 */
			voltage-ref = < 0x2 >;          /* in zephyr/dts/arm/nxp/nxp_mcxa156.dtsi:385 */
			calibration-average = < 0x80 >; /* in zephyr/dts/arm/nxp/nxp_mcxa156.dtsi:386 */
			power-level = < 0x0 >;          /* in zephyr/dts/arm/nxp/nxp_mcxa156.dtsi:387 */
			offset-value-a = < 0x0 >;       /* in zephyr/dts/arm/nxp/nxp_mcxa156.dtsi:388 */
			offset-value-b = < 0x0 >;       /* in zephyr/dts/arm/nxp/nxp_mcxa156.dtsi:389 */
			#io-channel-cells = < 0x1 >;    /* in zephyr/dts/arm/nxp/nxp_mcxa156.dtsi:390 */
			clocks = < &syscon 0xf00 >;     /* in zephyr/dts/arm/nxp/nxp_mcxa156.dtsi:391 */
			status = "okay";                /* in zephyr/boards/nxp/frdm_mcxa156/frdm_mcxa156.dts:227 */
			pinctrl-0 = < &pinmux_lpadc0 >; /* in zephyr/boards/nxp/frdm_mcxa156/frdm_mcxa156.dts:228 */
			pinctrl-names = "default";      /* in zephyr/boards/nxp/frdm_mcxa156/frdm_mcxa156.dts:229 */
		};

		/* node '/soc/lpadc@400b0000' defined in zephyr/dts/arm/nxp/nxp_mcxa156.dtsi:394 */
		lpadc1: lpadc@400b0000 {
			compatible = "nxp,lpc-lpadc";   /* in zephyr/dts/arm/nxp/nxp_mcxa156.dtsi:395 */
			reg = < 0x400b0000 0x1000 >;    /* in zephyr/dts/arm/nxp/nxp_mcxa156.dtsi:396 */
			interrupts = < 0x3f 0x0 >;      /* in zephyr/dts/arm/nxp/nxp_mcxa156.dtsi:397 */
			status = "disabled";            /* in zephyr/dts/arm/nxp/nxp_mcxa156.dtsi:398 */
			clk-divider = < 0x1 >;          /* in zephyr/dts/arm/nxp/nxp_mcxa156.dtsi:399 */
			clk-source = < 0x0 >;           /* in zephyr/dts/arm/nxp/nxp_mcxa156.dtsi:400 */
			voltage-ref = < 0x2 >;          /* in zephyr/dts/arm/nxp/nxp_mcxa156.dtsi:401 */
			calibration-average = < 0x80 >; /* in zephyr/dts/arm/nxp/nxp_mcxa156.dtsi:402 */
			power-level = < 0x1 >;          /* in zephyr/dts/arm/nxp/nxp_mcxa156.dtsi:403 */
			offset-value-a = < 0x0 >;       /* in zephyr/dts/arm/nxp/nxp_mcxa156.dtsi:404 */
			offset-value-b = < 0x0 >;       /* in zephyr/dts/arm/nxp/nxp_mcxa156.dtsi:405 */
			#io-channel-cells = < 0x1 >;    /* in zephyr/dts/arm/nxp/nxp_mcxa156.dtsi:406 */
			clocks = < &syscon 0xf01 >;     /* in zephyr/dts/arm/nxp/nxp_mcxa156.dtsi:407 */
		};

		/* node '/soc/lpcmp@400b1000' defined in zephyr/dts/arm/nxp/nxp_mcxa156.dtsi:410 */
		lpcmp0: lpcmp@400b1000 {
			compatible = "nxp,lpcmp";       /* in zephyr/dts/arm/nxp/nxp_mcxa156.dtsi:411 */
			reg = < 0x400b1000 0x1000 >;    /* in zephyr/dts/arm/nxp/nxp_mcxa156.dtsi:412 */
			interrupts = < 0x40 0x0 >;      /* in zephyr/dts/arm/nxp/nxp_mcxa156.dtsi:413 */
			#io-channel-cells = < 0x2 >;    /* in zephyr/dts/arm/nxp/nxp_mcxa156.dtsi:415 */
			status = "okay";                /* in zephyr/boards/nxp/frdm_mcxa156/frdm_mcxa156.dts:233 */
			pinctrl-0 = < &pinmux_lpcmp0 >; /* in zephyr/boards/nxp/frdm_mcxa156/frdm_mcxa156.dts:234 */
			pinctrl-names = "default";      /* in zephyr/boards/nxp/frdm_mcxa156/frdm_mcxa156.dts:235 */
		};

		/* node '/soc/lpcmp@400b2000' defined in zephyr/dts/arm/nxp/nxp_mcxa156.dtsi:418 */
		lpcmp1: lpcmp@400b2000 {
			compatible = "nxp,lpcmp";    /* in zephyr/dts/arm/nxp/nxp_mcxa156.dtsi:419 */
			reg = < 0x400b2000 0x1000 >; /* in zephyr/dts/arm/nxp/nxp_mcxa156.dtsi:420 */
			interrupts = < 0x41 0x0 >;   /* in zephyr/dts/arm/nxp/nxp_mcxa156.dtsi:421 */
			status = "disabled";         /* in zephyr/dts/arm/nxp/nxp_mcxa156.dtsi:422 */
			#io-channel-cells = < 0x2 >; /* in zephyr/dts/arm/nxp/nxp_mcxa156.dtsi:423 */
		};

		/* node '/soc/opamp@400b7000' defined in zephyr/dts/arm/nxp/nxp_mcxa156.dtsi:426 */
		opamp0: opamp@400b7000 {
			compatible = "nxp,opamp";       /* in zephyr/dts/arm/nxp/nxp_mcxa156.dtsi:427 */
			reg = < 0x400b7000 0x1000 >;    /* in zephyr/dts/arm/nxp/nxp_mcxa156.dtsi:428 */
			operation-mode = "low_noise";   /* in zephyr/dts/arm/nxp/nxp_mcxa156.dtsi:430 */
			functional-mode = "follower";   /* in zephyr/dts/arm/nxp/nxp_mcxa156.dtsi:431 */
			clocks = < &syscon 0x1800 >;    /* in zephyr/dts/arm/nxp/nxp_mcxa156.dtsi:432 */
			status = "okay";                /* in zephyr/boards/nxp/frdm_mcxa156/frdm_mcxa156.dts:239 */
			pinctrl-0 = < &pinmux_opamp0 >; /* in zephyr/boards/nxp/frdm_mcxa156/frdm_mcxa156.dts:240 */
			pinctrl-names = "default";      /* in zephyr/boards/nxp/frdm_mcxa156/frdm_mcxa156.dts:241 */
		};

		/* node '/soc/i2c@4009a000' defined in zephyr/dts/arm/nxp/nxp_mcxa156.dtsi:435 */
		lpi2c0: i2c@4009a000 {
			compatible = "nxp,lpi2c";       /* in zephyr/dts/arm/nxp/nxp_mcxa156.dtsi:436 */
			clock-frequency = < 0x186a0 >;  /* in zephyr/dts/arm/nxp/nxp_mcxa156.dtsi:437 */
			#address-cells = < 0x1 >;       /* in zephyr/dts/arm/nxp/nxp_mcxa156.dtsi:438 */
			#size-cells = < 0x0 >;          /* in zephyr/dts/arm/nxp/nxp_mcxa156.dtsi:439 */
			reg = < 0x4009a000 0x1000 >;    /* in zephyr/dts/arm/nxp/nxp_mcxa156.dtsi:440 */
			interrupts = < 0x1a 0x0 >;      /* in zephyr/dts/arm/nxp/nxp_mcxa156.dtsi:441 */
			clocks = < &syscon 0x1400 >;    /* in zephyr/dts/arm/nxp/nxp_mcxa156.dtsi:442 */
			status = "okay";                /* in zephyr/boards/nxp/frdm_mcxa156/frdm_mcxa156.dts:245 */
			pinctrl-0 = < &pinmux_lpi2c0 >; /* in zephyr/boards/nxp/frdm_mcxa156/frdm_mcxa156.dts:246 */
			pinctrl-names = "default";      /* in zephyr/boards/nxp/frdm_mcxa156/frdm_mcxa156.dts:247 */
		};

		/* node '/soc/i2c@4009b000' defined in zephyr/dts/arm/nxp/nxp_mcxa156.dtsi:446 */
		lpi2c1: i2c@4009b000 {
			compatible = "nxp,lpi2c";      /* in zephyr/dts/arm/nxp/nxp_mcxa156.dtsi:447 */
			clock-frequency = < 0x186a0 >; /* in zephyr/dts/arm/nxp/nxp_mcxa156.dtsi:448 */
			#address-cells = < 0x1 >;      /* in zephyr/dts/arm/nxp/nxp_mcxa156.dtsi:449 */
			#size-cells = < 0x0 >;         /* in zephyr/dts/arm/nxp/nxp_mcxa156.dtsi:450 */
			reg = < 0x4009b000 0x1000 >;   /* in zephyr/dts/arm/nxp/nxp_mcxa156.dtsi:451 */
			interrupts = < 0x1b 0x0 >;     /* in zephyr/dts/arm/nxp/nxp_mcxa156.dtsi:452 */
			clocks = < &syscon 0x1401 >;   /* in zephyr/dts/arm/nxp/nxp_mcxa156.dtsi:453 */
			status = "disabled";           /* in zephyr/dts/arm/nxp/nxp_mcxa156.dtsi:454 */
		};

		/* node '/soc/i2c@400d4000' defined in zephyr/dts/arm/nxp/nxp_mcxa156.dtsi:457 */
		lpi2c2: nxp_8080_touch_panel_i2c: i2c@400d4000 {
			compatible = "nxp,lpi2c";       /* in zephyr/dts/arm/nxp/nxp_mcxa156.dtsi:458 */
			clock-frequency = < 0x186a0 >;  /* in zephyr/dts/arm/nxp/nxp_mcxa156.dtsi:459 */
			#address-cells = < 0x1 >;       /* in zephyr/dts/arm/nxp/nxp_mcxa156.dtsi:460 */
			#size-cells = < 0x0 >;          /* in zephyr/dts/arm/nxp/nxp_mcxa156.dtsi:461 */
			reg = < 0x400d4000 0x1000 >;    /* in zephyr/dts/arm/nxp/nxp_mcxa156.dtsi:462 */
			interrupts = < 0x4d 0x0 >;      /* in zephyr/dts/arm/nxp/nxp_mcxa156.dtsi:463 */
			clocks = < &syscon 0x1402 >;    /* in zephyr/dts/arm/nxp/nxp_mcxa156.dtsi:464 */
			status = "disabled";            /* in zephyr/dts/arm/nxp/nxp_mcxa156.dtsi:465 */
			pinctrl-0 = < &pinmux_lpi2c2 >; /* in zephyr/boards/nxp/frdm_mcxa156/frdm_mcxa156.dts:184 */
			pinctrl-names = "default";      /* in zephyr/boards/nxp/frdm_mcxa156/frdm_mcxa156.dts:185 */
		};

		/* node '/soc/i2c@400d5000' defined in zephyr/dts/arm/nxp/nxp_mcxa156.dtsi:468 */
		lpi2c3: i2c@400d5000 {
			compatible = "nxp,lpi2c";       /* in zephyr/dts/arm/nxp/nxp_mcxa156.dtsi:469 */
			clock-frequency = < 0x186a0 >;  /* in zephyr/dts/arm/nxp/nxp_mcxa156.dtsi:470 */
			#address-cells = < 0x1 >;       /* in zephyr/dts/arm/nxp/nxp_mcxa156.dtsi:471 */
			#size-cells = < 0x0 >;          /* in zephyr/dts/arm/nxp/nxp_mcxa156.dtsi:472 */
			reg = < 0x400d5000 0x1000 >;    /* in zephyr/dts/arm/nxp/nxp_mcxa156.dtsi:473 */
			interrupts = < 0x4e 0x0 >;      /* in zephyr/dts/arm/nxp/nxp_mcxa156.dtsi:474 */
			clocks = < &syscon 0x1403 >;    /* in zephyr/dts/arm/nxp/nxp_mcxa156.dtsi:475 */
			status = "okay";                /* in zephyr/boards/nxp/frdm_mcxa156/frdm_mcxa156.dts:251 */
			pinctrl-0 = < &pinmux_lpi2c3 >; /* in zephyr/boards/nxp/frdm_mcxa156/frdm_mcxa156.dts:252 */
			pinctrl-names = "default";      /* in zephyr/boards/nxp/frdm_mcxa156/frdm_mcxa156.dts:253 */
		};

		/* node '/soc/spi@4009c000' defined in zephyr/dts/arm/nxp/nxp_mcxa156.dtsi:479 */
		lpspi0: spi@4009c000 {
			compatible = "nxp,lpspi";       /* in zephyr/dts/arm/nxp/nxp_mcxa156.dtsi:480 */
			reg = < 0x4009c000 0x1000 >;    /* in zephyr/dts/arm/nxp/nxp_mcxa156.dtsi:481 */
			interrupts = < 0x1c 0x0 >;      /* in zephyr/dts/arm/nxp/nxp_mcxa156.dtsi:482 */
			clocks = < &syscon 0x1700 >;    /* in zephyr/dts/arm/nxp/nxp_mcxa156.dtsi:483 */
			tx-fifo-size = < 0x4 >;         /* in zephyr/dts/arm/nxp/nxp_mcxa156.dtsi:484 */
			rx-fifo-size = < 0x4 >;         /* in zephyr/dts/arm/nxp/nxp_mcxa156.dtsi:485 */
			#address-cells = < 0x1 >;       /* in zephyr/dts/arm/nxp/nxp_mcxa156.dtsi:486 */
			#size-cells = < 0x0 >;          /* in zephyr/dts/arm/nxp/nxp_mcxa156.dtsi:487 */
			status = "okay";                /* in zephyr/boards/nxp/frdm_mcxa156/frdm_mcxa156.dts:257 */
			pinctrl-0 = < &pinmux_lpspi0 >; /* in zephyr/boards/nxp/frdm_mcxa156/frdm_mcxa156.dts:258 */
			pinctrl-names = "default";      /* in zephyr/boards/nxp/frdm_mcxa156/frdm_mcxa156.dts:259 */
		};

		/* node '/soc/spi@4009d000' defined in zephyr/dts/arm/nxp/nxp_mcxa156.dtsi:491 */
		lpspi1: spi@4009d000 {
			compatible = "nxp,lpspi";    /* in zephyr/dts/arm/nxp/nxp_mcxa156.dtsi:492 */
			reg = < 0x4009d000 0x1000 >; /* in zephyr/dts/arm/nxp/nxp_mcxa156.dtsi:493 */
			interrupts = < 0x1d 0x0 >;   /* in zephyr/dts/arm/nxp/nxp_mcxa156.dtsi:494 */
			clocks = < &syscon 0x1701 >; /* in zephyr/dts/arm/nxp/nxp_mcxa156.dtsi:495 */
			tx-fifo-size = < 0x4 >;      /* in zephyr/dts/arm/nxp/nxp_mcxa156.dtsi:496 */
			rx-fifo-size = < 0x4 >;      /* in zephyr/dts/arm/nxp/nxp_mcxa156.dtsi:497 */
			#address-cells = < 0x1 >;    /* in zephyr/dts/arm/nxp/nxp_mcxa156.dtsi:498 */
			#size-cells = < 0x0 >;       /* in zephyr/dts/arm/nxp/nxp_mcxa156.dtsi:499 */
			status = "disabled";         /* in zephyr/dts/arm/nxp/nxp_mcxa156.dtsi:500 */
		};

		/* node '/soc/lptmr@400ab000' defined in zephyr/dts/arm/nxp/nxp_mcxa156.dtsi:503 */
		lptmr0: lptmr@400ab000 {
			compatible = "nxp,lptmr";         /* in zephyr/dts/arm/nxp/nxp_mcxa156.dtsi:504 */
			reg = < 0x400ab000 0x1000 >;      /* in zephyr/dts/arm/nxp/nxp_mcxa156.dtsi:505 */
			interrupts = < 0x37 0x0 >;        /* in zephyr/dts/arm/nxp/nxp_mcxa156.dtsi:506 */
			clock-frequency = < 0x3e80 >;     /* in zephyr/dts/arm/nxp/nxp_mcxa156.dtsi:507 */
			prescale-glitch-filter = < 0x0 >; /* in zephyr/dts/arm/nxp/nxp_mcxa156.dtsi:508 */
			clk-source = < 0x1 >;             /* in zephyr/dts/arm/nxp/nxp_mcxa156.dtsi:509 */
			resolution = < 0x20 >;            /* in zephyr/dts/arm/nxp/nxp_mcxa156.dtsi:510 */
			status = "okay";                  /* in zephyr/boards/nxp/frdm_mcxa156/frdm_mcxa156.dts:263 */
		};

		/* node '/soc/timers@400ad000' defined in zephyr/dts/arm/nxp/nxp_mcxa156.dtsi:514 */
		ostimer0: timers@400ad000 {
			compatible = "nxp,os-timer"; /* in zephyr/dts/arm/nxp/nxp_mcxa156.dtsi:515 */
			reg = < 0x400ad000 0x1000 >; /* in zephyr/dts/arm/nxp/nxp_mcxa156.dtsi:516 */
			interrupts = < 0x39 0x0 >;   /* in zephyr/dts/arm/nxp/nxp_mcxa156.dtsi:517 */
			status = "okay";             /* in zephyr/boards/nxp/frdm_mcxa156/frdm_mcxa156.dts:270 */
		};

		/* node '/soc/temp0' defined in zephyr/dts/arm/nxp/nxp_mcxa156.dtsi:521 */
		temp0: temp0 {
			compatible = "nxp,lpadc-temp40"; /* in zephyr/dts/arm/nxp/nxp_mcxa156.dtsi:522 */
			status = "disabled";             /* in zephyr/dts/arm/nxp/nxp_mcxa156.dtsi:523 */
		};

		/* node '/soc/usbd@400a4000' defined in zephyr/dts/arm/nxp/nxp_mcxa156.dtsi:526 */
		usb: zephyr_udc0: usbd@400a4000 {
			compatible = "nxp,kinetis-usbd"; /* in zephyr/dts/arm/nxp/nxp_mcxa156.dtsi:527 */
			reg = < 0x400a4000 0x1000 >;     /* in zephyr/dts/arm/nxp/nxp_mcxa156.dtsi:528 */
			interrupts = < 0x24 0x1 >;       /* in zephyr/dts/arm/nxp/nxp_mcxa156.dtsi:529 */
			interrupt-names = "usb";         /* in zephyr/dts/arm/nxp/nxp_mcxa156.dtsi:530 */
			no-voltage-regulator;            /* in zephyr/dts/arm/nxp/nxp_mcxa156.dtsi:533 */
			status = "okay";                 /* in zephyr/boards/nxp/frdm_mcxa156/frdm_mcxa156.dts:274 */
			num-bidir-endpoints = < 0x8 >;   /* in zephyr/boards/nxp/frdm_mcxa156/frdm_mcxa156.dts:275 */
		};

		/* node '/soc/watchdog@4000c000' defined in zephyr/dts/arm/nxp/nxp_mcxa156.dtsi:536 */
		wwdt0: watchdog@4000c000 {
			compatible = "nxp,lpc-wwdt"; /* in zephyr/dts/arm/nxp/nxp_mcxa156.dtsi:537 */
			reg = < 0x4000c000 0x1000 >; /* in zephyr/dts/arm/nxp/nxp_mcxa156.dtsi:538 */
			interrupts = < 0x3c 0x0 >;   /* in zephyr/dts/arm/nxp/nxp_mcxa156.dtsi:539 */
			clk-divider = < 0x1 >;       /* in zephyr/dts/arm/nxp/nxp_mcxa156.dtsi:541 */
			status = "okay";             /* in zephyr/boards/nxp/frdm_mcxa156/frdm_mcxa156.dts:279 */
		};
	};

	/* node '/cpus' defined in zephyr/dts/arm/nxp/nxp_mcxa156.dtsi:15 */
	cpus {
		#address-cells = < 0x1 >; /* in zephyr/dts/arm/nxp/nxp_mcxa156.dtsi:16 */
		#size-cells = < 0x0 >;    /* in zephyr/dts/arm/nxp/nxp_mcxa156.dtsi:17 */

		/* node '/cpus/cpu@0' defined in zephyr/dts/arm/nxp/nxp_mcxa156.dtsi:19 */
		cpu0: cpu@0 {
			compatible = "arm,cortex-m33f";  /* in zephyr/dts/arm/nxp/nxp_mcxa156.dtsi:20 */
			reg = < 0x0 >;                   /* in zephyr/dts/arm/nxp/nxp_mcxa156.dtsi:21 */
			#address-cells = < 0x1 >;        /* in zephyr/dts/arm/nxp/nxp_mcxa156.dtsi:22 */
			#size-cells = < 0x1 >;           /* in zephyr/dts/arm/nxp/nxp_mcxa156.dtsi:23 */
			clock-frequency = < 0x5b8d800 >; /* in zephyr/boards/nxp/frdm_mcxa156/frdm_mcxa156.dts:122 */
		};
	};

	/* node '/pinctrl' defined in zephyr/dts/arm/nxp/nxp_mcxa156.dtsi:28 */
	pinctrl: pinctrl {
		compatible = "nxp,port-pinctrl"; /* in zephyr/dts/arm/nxp/nxp_mcxa156.dtsi:29 */
		status = "okay";                 /* in zephyr/dts/arm/nxp/nxp_mcxa156.dtsi:30 */

		/* node '/pinctrl/pinmux_lpuart0' defined in zephyr/boards/nxp/frdm_mcxa156/frdm_mcxa156-pinctrl.dtsi:9 */
		pinmux_lpuart0: pinmux_lpuart0 {
			phandle = < 0x9 >; /* in zephyr/boards/nxp/frdm_mcxa156/frdm_mcxa156.dts:148 */

			/* node '/pinctrl/pinmux_lpuart0/group0' defined in zephyr/boards/nxp/frdm_mcxa156/frdm_mcxa156-pinctrl.dtsi:10 */
			group0 {
				pinmux = < 0x800200 >,
				         < 0xc00200 >;  /* in zephyr/boards/nxp/frdm_mcxa156/frdm_mcxa156-pinctrl.dtsi:11 */
				drive-strength = "low"; /* in zephyr/boards/nxp/frdm_mcxa156/frdm_mcxa156-pinctrl.dtsi:13 */
				slew-rate = "fast";     /* in zephyr/boards/nxp/frdm_mcxa156/frdm_mcxa156-pinctrl.dtsi:14 */
				input-enable;           /* in zephyr/boards/nxp/frdm_mcxa156/frdm_mcxa156-pinctrl.dtsi:15 */
			};
		};

		/* node '/pinctrl/pinmux_lpuart1' defined in zephyr/boards/nxp/frdm_mcxa156/frdm_mcxa156-pinctrl.dtsi:19 */
		pinmux_lpuart1: pinmux_lpuart1 {
			phandle = < 0xa >; /* in zephyr/boards/nxp/frdm_mcxa156/frdm_mcxa156.dts:155 */

			/* node '/pinctrl/pinmux_lpuart1/group0' defined in zephyr/boards/nxp/frdm_mcxa156/frdm_mcxa156-pinctrl.dtsi:20 */
			group0 {
				pinmux = < 0x35000300 >,
				         < 0x35400300 >; /* in zephyr/boards/nxp/frdm_mcxa156/frdm_mcxa156-pinctrl.dtsi:21 */
				drive-strength = "low";  /* in zephyr/boards/nxp/frdm_mcxa156/frdm_mcxa156-pinctrl.dtsi:23 */
				slew-rate = "fast";      /* in zephyr/boards/nxp/frdm_mcxa156/frdm_mcxa156-pinctrl.dtsi:24 */
				input-enable;            /* in zephyr/boards/nxp/frdm_mcxa156/frdm_mcxa156-pinctrl.dtsi:25 */
			};
		};

		/* node '/pinctrl/pinmux_dac0' defined in zephyr/boards/nxp/frdm_mcxa156/frdm_mcxa156-pinctrl.dtsi:29 */
		pinmux_dac0: pinmux_dac0 {
			phandle = < 0xb >; /* in zephyr/boards/nxp/frdm_mcxa156/frdm_mcxa156.dts:165 */

			/* node '/pinctrl/pinmux_dac0/group0' defined in zephyr/boards/nxp/frdm_mcxa156/frdm_mcxa156-pinctrl.dtsi:30 */
			group0 {
				pinmux = < 0x20800000 >; /* in zephyr/boards/nxp/frdm_mcxa156/frdm_mcxa156-pinctrl.dtsi:31 */
				drive-strength = "low";  /* in zephyr/boards/nxp/frdm_mcxa156/frdm_mcxa156-pinctrl.dtsi:32 */
				slew-rate = "fast";      /* in zephyr/boards/nxp/frdm_mcxa156/frdm_mcxa156-pinctrl.dtsi:33 */
			};
		};

		/* node '/pinctrl/pinmux_flexcan0' defined in zephyr/boards/nxp/frdm_mcxa156/frdm_mcxa156-pinctrl.dtsi:37 */
		pinmux_flexcan0: pinmux_flexcan0 {
			phandle = < 0xc >; /* in zephyr/boards/nxp/frdm_mcxa156/frdm_mcxa156.dts:175 */

			/* node '/pinctrl/pinmux_flexcan0/group0' defined in zephyr/boards/nxp/frdm_mcxa156/frdm_mcxa156-pinctrl.dtsi:38 */
			group0 {
				pinmux = < 0x13400b00 >,
				         < 0x13000b00 >; /* in zephyr/boards/nxp/frdm_mcxa156/frdm_mcxa156-pinctrl.dtsi:39 */
				slew-rate = "fast";      /* in zephyr/boards/nxp/frdm_mcxa156/frdm_mcxa156-pinctrl.dtsi:41 */
				drive-strength = "low";  /* in zephyr/boards/nxp/frdm_mcxa156/frdm_mcxa156-pinctrl.dtsi:42 */
				input-enable;            /* in zephyr/boards/nxp/frdm_mcxa156/frdm_mcxa156-pinctrl.dtsi:43 */
			};
		};

		/* node '/pinctrl/pinmux_flexio_lcd' defined in zephyr/boards/nxp/frdm_mcxa156/frdm_mcxa156-pinctrl.dtsi:47 */
		pinmux_flexio_lcd: pinmux_flexio_lcd {
			phandle = < 0xf >; /* in zephyr/boards/nxp/frdm_mcxa156/frdm_mcxa156.dts:200 */

			/* node '/pinctrl/pinmux_flexio_lcd/group0' defined in zephyr/boards/nxp/frdm_mcxa156/frdm_mcxa156-pinctrl.dtsi:48 */
			group0 {
				pinmux = < 0x4000600 >,
				         < 0x4400600 >,
				         < 0x4800600 >,
				         < 0x4c00600 >,
				         < 0x5000600 >,
				         < 0x5400600 >,
				         < 0x5800600 >,
				         < 0x5c00600 >,
				         < 0x20000600 >,
				         < 0x20400600 >,
				         < 0x40800600 >,
				         < 0x40c00600 >,
				         < 0x41000600 >,
				         < 0x41400600 >,
				         < 0x41800600 >,
				         < 0x41c00600 >,
				         < 0x24400000 >,
				         < 0x24c00000 >,
				         < 0x30000000 >; /* in zephyr/boards/nxp/frdm_mcxa156/frdm_mcxa156-pinctrl.dtsi:49 */
				slew-rate = "fast";      /* in zephyr/boards/nxp/frdm_mcxa156/frdm_mcxa156-pinctrl.dtsi:68 */
				drive-strength = "low";  /* in zephyr/boards/nxp/frdm_mcxa156/frdm_mcxa156-pinctrl.dtsi:69 */
				input-enable;            /* in zephyr/boards/nxp/frdm_mcxa156/frdm_mcxa156-pinctrl.dtsi:70 */
			};

			/* node '/pinctrl/pinmux_flexio_lcd/group1' defined in zephyr/boards/nxp/frdm_mcxa156/frdm_mcxa156-pinctrl.dtsi:73 */
			group1 {
				pinmux = < 0x25000600 >; /* in zephyr/boards/nxp/frdm_mcxa156/frdm_mcxa156-pinctrl.dtsi:74 */
				slew-rate = "fast";      /* in zephyr/boards/nxp/frdm_mcxa156/frdm_mcxa156-pinctrl.dtsi:75 */
				drive-strength = "low";  /* in zephyr/boards/nxp/frdm_mcxa156/frdm_mcxa156-pinctrl.dtsi:76 */
				input-enable;            /* in zephyr/boards/nxp/frdm_mcxa156/frdm_mcxa156-pinctrl.dtsi:77 */
				bias-pull-up;            /* in zephyr/boards/nxp/frdm_mcxa156/frdm_mcxa156-pinctrl.dtsi:78 */
			};

			/* node '/pinctrl/pinmux_flexio_lcd/group2' defined in zephyr/boards/nxp/frdm_mcxa156/frdm_mcxa156-pinctrl.dtsi:81 */
			group2 {
				pinmux = < 0x25c00600 >; /* in zephyr/boards/nxp/frdm_mcxa156/frdm_mcxa156-pinctrl.dtsi:82 */
				slew-rate = "slow";      /* in zephyr/boards/nxp/frdm_mcxa156/frdm_mcxa156-pinctrl.dtsi:83 */
				drive-strength = "low";  /* in zephyr/boards/nxp/frdm_mcxa156/frdm_mcxa156-pinctrl.dtsi:84 */
				input-enable;            /* in zephyr/boards/nxp/frdm_mcxa156/frdm_mcxa156-pinctrl.dtsi:85 */
				bias-pull-up;            /* in zephyr/boards/nxp/frdm_mcxa156/frdm_mcxa156-pinctrl.dtsi:86 */
			};
		};

		/* node '/pinctrl/pinmux_flexpwm0_pwm0' defined in zephyr/boards/nxp/frdm_mcxa156/frdm_mcxa156-pinctrl.dtsi:90 */
		pinmux_flexpwm0_pwm0: pinmux_flexpwm0_pwm0 {
			phandle = < 0x10 >; /* in zephyr/boards/nxp/frdm_mcxa156/frdm_mcxa156.dts:206 */

			/* node '/pinctrl/pinmux_flexpwm0_pwm0/group0' defined in zephyr/boards/nxp/frdm_mcxa156/frdm_mcxa156-pinctrl.dtsi:91 */
			group0 {
				pinmux = < 0x31800500 >,
				         < 0x31c00500 >; /* in zephyr/boards/nxp/frdm_mcxa156/frdm_mcxa156-pinctrl.dtsi:92 */
				slew-rate = "fast";      /* in zephyr/boards/nxp/frdm_mcxa156/frdm_mcxa156-pinctrl.dtsi:94 */
				drive-strength = "low";  /* in zephyr/boards/nxp/frdm_mcxa156/frdm_mcxa156-pinctrl.dtsi:95 */
			};
		};

		/* node '/pinctrl/pinmux_i3c0' defined in zephyr/boards/nxp/frdm_mcxa156/frdm_mcxa156-pinctrl.dtsi:99 */
		pinmux_i3c0: pinmux_i3c0 {
			phandle = < 0x11 >; /* in zephyr/boards/nxp/frdm_mcxa156/frdm_mcxa156.dts:212 */

			/* node '/pinctrl/pinmux_i3c0/group0' defined in zephyr/boards/nxp/frdm_mcxa156/frdm_mcxa156-pinctrl.dtsi:100 */
			group0 {
				pinmux = < 0x4000a00 >,
				         < 0x4400a00 >; /* in zephyr/boards/nxp/frdm_mcxa156/frdm_mcxa156-pinctrl.dtsi:101 */
				slew-rate = "fast";     /* in zephyr/boards/nxp/frdm_mcxa156/frdm_mcxa156-pinctrl.dtsi:103 */
				drive-strength = "low"; /* in zephyr/boards/nxp/frdm_mcxa156/frdm_mcxa156-pinctrl.dtsi:104 */
				input-enable;           /* in zephyr/boards/nxp/frdm_mcxa156/frdm_mcxa156-pinctrl.dtsi:105 */
				bias-pull-up;           /* in zephyr/boards/nxp/frdm_mcxa156/frdm_mcxa156-pinctrl.dtsi:106 */
			};

			/* node '/pinctrl/pinmux_i3c0/group1' defined in zephyr/boards/nxp/frdm_mcxa156/frdm_mcxa156-pinctrl.dtsi:109 */
			group1 {
				pinmux = < 0x12c00a00 >; /* in zephyr/boards/nxp/frdm_mcxa156/frdm_mcxa156-pinctrl.dtsi:110 */
				slew-rate = "fast";      /* in zephyr/boards/nxp/frdm_mcxa156/frdm_mcxa156-pinctrl.dtsi:111 */
				drive-strength = "low";  /* in zephyr/boards/nxp/frdm_mcxa156/frdm_mcxa156-pinctrl.dtsi:112 */
				input-enable;            /* in zephyr/boards/nxp/frdm_mcxa156/frdm_mcxa156-pinctrl.dtsi:113 */
			};
		};

		/* node '/pinctrl/pinmux_lpadc0' defined in zephyr/boards/nxp/frdm_mcxa156/frdm_mcxa156-pinctrl.dtsi:117 */
		pinmux_lpadc0: pinmux_lpadc0 {
			phandle = < 0x12 >; /* in zephyr/boards/nxp/frdm_mcxa156/frdm_mcxa156.dts:228 */

			/* node '/pinctrl/pinmux_lpadc0/group0' defined in zephyr/boards/nxp/frdm_mcxa156/frdm_mcxa156-pinctrl.dtsi:118 */
			group0 {
				pinmux = < 0x20000000 >,
				         < 0x20400000 >; /* in zephyr/boards/nxp/frdm_mcxa156/frdm_mcxa156-pinctrl.dtsi:119 */
				slew-rate = "fast";      /* in zephyr/boards/nxp/frdm_mcxa156/frdm_mcxa156-pinctrl.dtsi:121 */
				drive-strength = "low";  /* in zephyr/boards/nxp/frdm_mcxa156/frdm_mcxa156-pinctrl.dtsi:122 */
			};
		};

		/* node '/pinctrl/pinmux_lpcmp0' defined in zephyr/boards/nxp/frdm_mcxa156/frdm_mcxa156-pinctrl.dtsi:126 */
		pinmux_lpcmp0: pinmux_lpcmp0 {
			phandle = < 0x13 >; /* in zephyr/boards/nxp/frdm_mcxa156/frdm_mcxa156.dts:234 */

			/* node '/pinctrl/pinmux_lpcmp0/group0' defined in zephyr/boards/nxp/frdm_mcxa156/frdm_mcxa156-pinctrl.dtsi:127 */
			group0 {
				pinmux = < 0x20800000 >; /* in zephyr/boards/nxp/frdm_mcxa156/frdm_mcxa156-pinctrl.dtsi:128 */
				drive-strength = "low";  /* in zephyr/boards/nxp/frdm_mcxa156/frdm_mcxa156-pinctrl.dtsi:129 */
				slew-rate = "fast";      /* in zephyr/boards/nxp/frdm_mcxa156/frdm_mcxa156-pinctrl.dtsi:130 */
				bias-pull-up;            /* in zephyr/boards/nxp/frdm_mcxa156/frdm_mcxa156-pinctrl.dtsi:131 */
			};
		};

		/* node '/pinctrl/pinmux_opamp0' defined in zephyr/boards/nxp/frdm_mcxa156/frdm_mcxa156-pinctrl.dtsi:135 */
		pinmux_opamp0: pinmux_opamp0 {
			phandle = < 0x14 >; /* in zephyr/boards/nxp/frdm_mcxa156/frdm_mcxa156.dts:240 */

			/* node '/pinctrl/pinmux_opamp0/group0' defined in zephyr/boards/nxp/frdm_mcxa156/frdm_mcxa156-pinctrl.dtsi:136 */
			group0 {
				pinmux = < 0x23000000 >,
				         < 0x23400000 >; /* in zephyr/boards/nxp/frdm_mcxa156/frdm_mcxa156-pinctrl.dtsi:137 */
				drive-strength = "low";  /* in zephyr/boards/nxp/frdm_mcxa156/frdm_mcxa156-pinctrl.dtsi:139 */
				slew-rate = "fast";      /* in zephyr/boards/nxp/frdm_mcxa156/frdm_mcxa156-pinctrl.dtsi:140 */
			};
		};

		/* node '/pinctrl/pinmux_lpi2c0' defined in zephyr/boards/nxp/frdm_mcxa156/frdm_mcxa156-pinctrl.dtsi:144 */
		pinmux_lpi2c0: pinmux_lpi2c0 {
			phandle = < 0x15 >; /* in zephyr/boards/nxp/frdm_mcxa156/frdm_mcxa156.dts:246 */

			/* node '/pinctrl/pinmux_lpi2c0/group0' defined in zephyr/boards/nxp/frdm_mcxa156/frdm_mcxa156-pinctrl.dtsi:145 */
			group0 {
				pinmux = < 0x4000200 >,
				         < 0x4400200 >; /* in zephyr/boards/nxp/frdm_mcxa156/frdm_mcxa156-pinctrl.dtsi:146 */
				slew-rate = "fast";     /* in zephyr/boards/nxp/frdm_mcxa156/frdm_mcxa156-pinctrl.dtsi:148 */
				drive-strength = "low"; /* in zephyr/boards/nxp/frdm_mcxa156/frdm_mcxa156-pinctrl.dtsi:149 */
				input-enable;           /* in zephyr/boards/nxp/frdm_mcxa156/frdm_mcxa156-pinctrl.dtsi:150 */
				bias-pull-up;           /* in zephyr/boards/nxp/frdm_mcxa156/frdm_mcxa156-pinctrl.dtsi:151 */
				drive-open-drain;       /* in zephyr/boards/nxp/frdm_mcxa156/frdm_mcxa156-pinctrl.dtsi:152 */
			};
		};

		/* node '/pinctrl/pinmux_lpi2c2' defined in zephyr/boards/nxp/frdm_mcxa156/frdm_mcxa156-pinctrl.dtsi:156 */
		pinmux_lpi2c2: pinmux_lpi2c2 {
			phandle = < 0x16 >; /* in zephyr/boards/nxp/frdm_mcxa156/frdm_mcxa156.dts:184 */

			/* node '/pinctrl/pinmux_lpi2c2/group0' defined in zephyr/boards/nxp/frdm_mcxa156/frdm_mcxa156-pinctrl.dtsi:157 */
			group0 {
				pinmux = < 0x12000300 >,
				         < 0x12400300 >; /* in zephyr/boards/nxp/frdm_mcxa156/frdm_mcxa156-pinctrl.dtsi:158 */
				slew-rate = "fast";      /* in zephyr/boards/nxp/frdm_mcxa156/frdm_mcxa156-pinctrl.dtsi:160 */
				drive-strength = "low";  /* in zephyr/boards/nxp/frdm_mcxa156/frdm_mcxa156-pinctrl.dtsi:161 */
				input-enable;            /* in zephyr/boards/nxp/frdm_mcxa156/frdm_mcxa156-pinctrl.dtsi:162 */
				bias-pull-up;            /* in zephyr/boards/nxp/frdm_mcxa156/frdm_mcxa156-pinctrl.dtsi:163 */
				drive-open-drain;        /* in zephyr/boards/nxp/frdm_mcxa156/frdm_mcxa156-pinctrl.dtsi:164 */
			};
		};

		/* node '/pinctrl/pinmux_lpi2c3' defined in zephyr/boards/nxp/frdm_mcxa156/frdm_mcxa156-pinctrl.dtsi:168 */
		pinmux_lpi2c3: pinmux_lpi2c3 {
			phandle = < 0x17 >; /* in zephyr/boards/nxp/frdm_mcxa156/frdm_mcxa156.dts:252 */

			/* node '/pinctrl/pinmux_lpi2c3/group0' defined in zephyr/boards/nxp/frdm_mcxa156/frdm_mcxa156-pinctrl.dtsi:169 */
			group0 {
				pinmux = < 0x37000200 >,
				         < 0x36c00200 >; /* in zephyr/boards/nxp/frdm_mcxa156/frdm_mcxa156-pinctrl.dtsi:170 */
				slew-rate = "fast";      /* in zephyr/boards/nxp/frdm_mcxa156/frdm_mcxa156-pinctrl.dtsi:172 */
				drive-strength = "low";  /* in zephyr/boards/nxp/frdm_mcxa156/frdm_mcxa156-pinctrl.dtsi:173 */
				input-enable;            /* in zephyr/boards/nxp/frdm_mcxa156/frdm_mcxa156-pinctrl.dtsi:174 */
				bias-pull-up;            /* in zephyr/boards/nxp/frdm_mcxa156/frdm_mcxa156-pinctrl.dtsi:175 */
				drive-open-drain;        /* in zephyr/boards/nxp/frdm_mcxa156/frdm_mcxa156-pinctrl.dtsi:176 */
			};
		};

		/* node '/pinctrl/pinmux_lpspi0' defined in zephyr/boards/nxp/frdm_mcxa156/frdm_mcxa156-pinctrl.dtsi:180 */
		pinmux_lpspi0: pinmux_lpspi0 {
			phandle = < 0x18 >; /* in zephyr/boards/nxp/frdm_mcxa156/frdm_mcxa156.dts:258 */

			/* node '/pinctrl/pinmux_lpspi0/group0' defined in zephyr/boards/nxp/frdm_mcxa156/frdm_mcxa156-pinctrl.dtsi:181 */
			group0 {
				pinmux = < 0x10000200 >,
				         < 0x10400200 >,
				         < 0x10800200 >,
				         < 0x10c00200 >; /* in zephyr/boards/nxp/frdm_mcxa156/frdm_mcxa156-pinctrl.dtsi:182 */
				slew-rate = "fast";      /* in zephyr/boards/nxp/frdm_mcxa156/frdm_mcxa156-pinctrl.dtsi:186 */
				drive-strength = "low";  /* in zephyr/boards/nxp/frdm_mcxa156/frdm_mcxa156-pinctrl.dtsi:187 */
				input-enable;            /* in zephyr/boards/nxp/frdm_mcxa156/frdm_mcxa156-pinctrl.dtsi:188 */
			};
		};
	};

	/* node '/cmc' defined in zephyr/dts/arm/nxp/nxp_mcxa156.dtsi:33 */
	cmc {
		compatible = "nxp,cmc-reset-cause"; /* in zephyr/dts/arm/nxp/nxp_mcxa156.dtsi:34 */
	};

	/* node '/leds' defined in zephyr/boards/nxp/frdm_mcxa156/frdm_mcxa156.dts:43 */
	leds {
		compatible = "gpio-leds"; /* in zephyr/boards/nxp/frdm_mcxa156/frdm_mcxa156.dts:44 */

		/* node '/leds/led_0' defined in zephyr/boards/nxp/frdm_mcxa156/frdm_mcxa156.dts:46 */
		red_led: led_0 {
			gpios = < &gpio3 0xc 0x1 >; /* in zephyr/boards/nxp/frdm_mcxa156/frdm_mcxa156.dts:47 */
			label = "Red LED";          /* in zephyr/boards/nxp/frdm_mcxa156/frdm_mcxa156.dts:48 */
		};

		/* node '/leds/led_1' defined in zephyr/boards/nxp/frdm_mcxa156/frdm_mcxa156.dts:51 */
		green_led: led_1 {
			gpios = < &gpio3 0xd 0x1 >; /* in zephyr/boards/nxp/frdm_mcxa156/frdm_mcxa156.dts:52 */
			label = "Green LED";        /* in zephyr/boards/nxp/frdm_mcxa156/frdm_mcxa156.dts:53 */
		};

		/* node '/leds/led_2' defined in zephyr/boards/nxp/frdm_mcxa156/frdm_mcxa156.dts:56 */
		blue_led: led_2 {
			gpios = < &gpio3 0x0 0x1 >; /* in zephyr/boards/nxp/frdm_mcxa156/frdm_mcxa156.dts:57 */
			label = "Blue LED";         /* in zephyr/boards/nxp/frdm_mcxa156/frdm_mcxa156.dts:58 */
		};
	};

	/* node '/gpio_keys' defined in zephyr/boards/nxp/frdm_mcxa156/frdm_mcxa156.dts:62 */
	gpio_keys {
		compatible = "gpio-keys"; /* in zephyr/boards/nxp/frdm_mcxa156/frdm_mcxa156.dts:63 */

		/* node '/gpio_keys/button_2' defined in zephyr/boards/nxp/frdm_mcxa156/frdm_mcxa156.dts:65 */
		user_button_2: button_2 {
			label = "User SW2";         /* in zephyr/boards/nxp/frdm_mcxa156/frdm_mcxa156.dts:66 */
			gpios = < &gpio1 0x7 0x1 >; /* in zephyr/boards/nxp/frdm_mcxa156/frdm_mcxa156.dts:67 */
			zephyr,code = < 0xb >;      /* in zephyr/boards/nxp/frdm_mcxa156/frdm_mcxa156.dts:68 */
		};

		/* node '/gpio_keys/button_3' defined in zephyr/boards/nxp/frdm_mcxa156/frdm_mcxa156.dts:71 */
		user_button_3: button_3 {
			label = "User SW3";         /* in zephyr/boards/nxp/frdm_mcxa156/frdm_mcxa156.dts:72 */
			gpios = < &gpio0 0x6 0x1 >; /* in zephyr/boards/nxp/frdm_mcxa156/frdm_mcxa156.dts:73 */
			zephyr,code = < 0x2 >;      /* in zephyr/boards/nxp/frdm_mcxa156/frdm_mcxa156.dts:74 */
		};
	};

	/* node '/lcd-8080-connector' defined in zephyr/boards/nxp/frdm_mcxa156/frdm_mcxa156.dts:81 */
	nxp_lcd_8080_connector: lcd-8080-connector {
		compatible = "nxp,lcd-8080";               /* in zephyr/boards/nxp/frdm_mcxa156/frdm_mcxa156.dts:82 */
		#gpio-cells = < 0x2 >;                     /* in zephyr/boards/nxp/frdm_mcxa156/frdm_mcxa156.dts:83 */
		gpio-map-mask = < 0xffffffff 0xffffffc0 >; /* in zephyr/boards/nxp/frdm_mcxa156/frdm_mcxa156.dts:84 */
		gpio-map-pass-thru = < 0x0 0x3f >;         /* in zephyr/boards/nxp/frdm_mcxa156/frdm_mcxa156.dts:85 */
		gpio-map = < 0x9 0x0 &gpio2 0xf 0x0 >,
		           < 0xa 0x0 &gpio3 0x16 0x0 >,
		           < 0xb 0x0 &gpio3 0x0 0x0 >;     /* in zephyr/boards/nxp/frdm_mcxa156/frdm_mcxa156.dts:86 */
	};

	/* node '/arduino-connector' defined in zephyr/boards/nxp/frdm_mcxa156/frdm_mcxa156.dts:91 */
	arduino_header: arduino-connector {
		compatible = "arduino-header-r3";          /* in zephyr/boards/nxp/frdm_mcxa156/frdm_mcxa156.dts:92 */
		#gpio-cells = < 0x2 >;                     /* in zephyr/boards/nxp/frdm_mcxa156/frdm_mcxa156.dts:93 */
		gpio-map-mask = < 0xffffffff 0xffffffc0 >; /* in zephyr/boards/nxp/frdm_mcxa156/frdm_mcxa156.dts:94 */
		gpio-map-pass-thru = < 0x0 0x3f >;         /* in zephyr/boards/nxp/frdm_mcxa156/frdm_mcxa156.dts:95 */
		gpio-map = < 0x0 0x0 &gpio1 0xa 0x0 >,
		           < 0x1 0x0 &gpio2 0x5 0x0 >,
		           < 0x2 0x0 &gpio2 0x3 0x0 >,
		           < 0x3 0x0 &gpio2 0x4 0x0 >,
		           < 0x4 0x0 &gpio1 0xc 0x0 >,
		           < 0x5 0x0 &gpio1 0xd 0x0 >,
		           < 0x6 0x0 &gpio2 0xb 0x0 >,
		           < 0x7 0x0 &gpio2 0xa 0x0 >,
		           < 0x8 0x0 &gpio3 0x1 0x0 >,
		           < 0x9 0x0 &gpio3 0xc 0x0 >,
		           < 0xa 0x0 &gpio3 0x1f 0x0 >,
		           < 0xb 0x0 &gpio3 0xe 0x0 >,
		           < 0xc 0x0 &gpio3 0x10 0x0 >,
		           < 0xd 0x0 &gpio1 0xe 0x0 >,
		           < 0xe 0x0 &gpio1 0xf 0x0 >,
		           < 0xf 0x0 &gpio3 0x11 0x0 >,
		           < 0x10 0x0 &gpio3 0xd 0x0 >,
		           < 0x11 0x0 &gpio3 0xf 0x0 >,
		           < 0x12 0x0 &gpio2 0x10 0x0 >,
		           < 0x13 0x0 &gpio2 0xc 0x0 >,
		           < 0x14 0x0 &gpio0 0x10 0x0 >,
		           < 0x15 0x0 &gpio0 0x11 0x0 >;   /* in zephyr/boards/nxp/frdm_mcxa156/frdm_mcxa156.dts:96 */
	};
};
